VERSION ""

NS_ :

BS_:

BU_:

BO_ 2566739710 DM50: 78 Vector__XXX
 SG_ FlashRedStopLamp : 12|2@1+ (1,0) [0|3] "" Vector__XXX
 SG_ FlashProtectLamp : 8|2@1+ (1,0) [0|3] "" Vector__XXX
 SG_ FlashMalfuncIndicatorLamp : 14|2@1+ (1,0) [0|3] "" Vector__XXX
 SG_ FlashAmberWarningLamp : 10|2@1+ (1,0) [0|3] "" Vector__XXX
 SG_ MalfunctionIndicatorLampStatus : 6|2@1+ (1,0) [0|3] "" Vector__XXX
 SG_ AmberWarningLampStatus : 2|2@1+ (1,0) [0|3] "" Vector__XXX
 SG_ RedStopLampStatus : 4|2@1+ (1,0) [0|3] "" Vector__XXX
 SG_ ProtectLampStatus : 0|2@1+ (1,0) [0|3] "" Vector__XXX
 SG_ DM50_01OC : 40|7@1+ (1,0) [0|0] "" Vector__XXX
 SG_ DM50_01FMI : 32|5@1+ (1,0) [0|0] "" Vector__XXX
 SG_ DM50_01SPN : 16|16@1+ (1,0) [0|0] "" Vector__XXX
 SG_ DM50_02OC : 72|7@1+ (1,0) [0|0] "" Vector__XXX
 SG_ DM50_02FMI : 64|5@1+ (1,0) [0|0] "" Vector__XXX
 SG_ DM50_02SPN : 48|16@1+ (1,0) [0|0] "" Vector__XXX
 SG_ DM50_03OC : 104|7@1+ (1,0) [0|0] "" Vector__XXX
 SG_ DM50_03FMI : 96|5@1+ (1,0) [0|0] "" Vector__XXX
 SG_ DM50_03SPN : 80|16@1+ (1,0) [0|0] "" Vector__XXX
 SG_ DM50_04OC : 136|7@1+ (1,0) [0|0] "" Vector__XXX
 SG_ DM50_04FMI : 128|5@1+ (1,0) [0|0] "" Vector__XXX
 SG_ DM50_04SPN : 112|16@1+ (1,0) [0|0] "" Vector__XXX
 SG_ DM50_05OC : 168|7@1+ (1,0) [0|0] "" Vector__XXX
 SG_ DM50_05FMI : 160|5@1+ (1,0) [0|0] "" Vector__XXX
 SG_ DM50_05SPN : 144|16@1+ (1,0) [0|0] "" Vector__XXX
 SG_ DM50_06OC : 200|7@1+ (1,0) [0|0] "" Vector__XXX
 SG_ DM50_06FMI : 192|5@1+ (1,0) [0|0] "" Vector__XXX
 SG_ DM50_06SPN : 176|16@1+ (1,0) [0|0] "" Vector__XXX
 SG_ DM50_07OC : 232|7@1+ (1,0) [0|0] "" Vector__XXX
 SG_ DM50_07FMI : 224|5@1+ (1,0) [0|0] "" Vector__XXX
 SG_ DM50_07SPN : 208|16@1+ (1,0) [0|0] "" Vector__XXX
 SG_ DM50_08OC : 264|7@1+ (1,0) [0|0] "" Vector__XXX
 SG_ DM50_08FMI : 256|5@1+ (1,0) [0|0] "" Vector__XXX
 SG_ DM50_08SPN : 240|16@1+ (1,0) [0|0] "" Vector__XXX
 SG_ DM50_09OC : 296|7@1+ (1,0) [0|0] "" Vector__XXX
 SG_ DM50_09FMI : 288|5@1+ (1,0) [0|0] "" Vector__XXX
 SG_ DM50_09SPN : 272|16@1+ (1,0) [0|0] "" Vector__XXX
 SG_ DM50_10OC : 328|7@1+ (1,0) [0|0] "" Vector__XXX
 SG_ DM50_10FMI : 320|5@1+ (1,0) [0|0] "" Vector__XXX
 SG_ DM50_10SPN : 304|16@1+ (1,0) [0|0] "" Vector__XXX
 SG_ DM50_11OC : 360|7@1+ (1,0) [0|0] "" Vector__XXX
 SG_ DM50_11FMI : 352|5@1+ (1,0) [0|0] "" Vector__XXX
 SG_ DM50_11SPN : 336|16@1+ (1,0) [0|0] "" Vector__XXX
 SG_ DM50_12OC : 392|7@1+ (1,0) [0|0] "" Vector__XXX
 SG_ DM50_12FMI : 384|5@1+ (1,0) [0|0] "" Vector__XXX
 SG_ DM50_12SPN : 368|16@1+ (1,0) [0|0] "" Vector__XXX
 SG_ DM50_13OC : 424|7@1+ (1,0) [0|0] "" Vector__XXX
 SG_ DM50_13FMI : 416|5@1+ (1,0) [0|0] "" Vector__XXX
 SG_ DM50_13SPN : 400|16@1+ (1,0) [0|0] "" Vector__XXX
 SG_ DM50_14OC : 456|7@1+ (1,0) [0|0] "" Vector__XXX
 SG_ DM50_14FMI : 448|5@1+ (1,0) [0|0] "" Vector__XXX
 SG_ DM50_14SPN : 432|16@1+ (1,0) [0|0] "" Vector__XXX
 SG_ DM50_15OC : 488|7@1+ (1,0) [0|0] "" Vector__XXX
 SG_ DM50_15FMI : 480|5@1+ (1,0) [0|0] "" Vector__XXX
 SG_ DM50_15SPN : 464|16@1+ (1,0) [0|0] "" Vector__XXX
 SG_ DM50_16OC : 520|7@1+ (1,0) [0|0] "" Vector__XXX
 SG_ DM50_16FMI : 512|5@1+ (1,0) [0|0] "" Vector__XXX
 SG_ DM50_16SPN : 496|16@1+ (1,0) [0|0] "" Vector__XXX
 SG_ DM50_17OC : 552|7@1+ (1,0) [0|0] "" Vector__XXX
 SG_ DM50_17FMI : 544|5@1+ (1,0) [0|0] "" Vector__XXX
 SG_ DM50_17SPN : 528|16@1+ (1,0) [0|0] "" Vector__XXX
 SG_ DM50_18OC : 584|7@1+ (1,0) [0|0] "" Vector__XXX
 SG_ DM50_18FMI : 576|5@1+ (1,0) [0|0] "" Vector__XXX
 SG_ DM50_18SPN : 560|16@1+ (1,0) [0|0] "" Vector__XXX
 SG_ DM50_19OC : 616|7@1+ (1,0) [0|0] "" Vector__XXX
 SG_ DM50_19FMI : 608|5@1+ (1,0) [0|0] "" Vector__XXX
 SG_ DM50_19SPN : 592|16@1+ (1,0) [0|0] "" Vector__XXX
 SG_ DM50_19SPN_High : 613|3@1+ (65536,0) [0|0] "" Vector__XXX
 SG_ DM50_18SPN_High : 581|3@1+ (65536,0) [0|0] "" Vector__XXX
 SG_ DM50_17SPN_High : 549|3@1+ (65536,0) [0|0] "" Vector__XXX
 SG_ DM50_16SPN_High : 517|3@1+ (65536,0) [0|0] "" Vector__XXX
 SG_ DM50_15SPN_High : 485|3@1+ (65536,0) [0|0] "" Vector__XXX
 SG_ DM50_14SPN_High : 453|3@1+ (65536,0) [0|0] "" Vector__XXX
 SG_ DM50_13SPN_High : 421|3@1+ (65536,0) [0|0] "" Vector__XXX
 SG_ DM50_12SPN_High : 389|3@1+ (65536,0) [0|0] "" Vector__XXX
 SG_ DM50_11SPN_High : 357|3@1+ (65536,0) [0|0] "" Vector__XXX
 SG_ DM50_10SPN_High : 325|3@1+ (65536,0) [0|0] "" Vector__XXX
 SG_ DM50_09SPN_High : 293|3@1+ (65536,0) [0|0] "" Vector__XXX
 SG_ DM50_08SPN_High : 261|3@1+ (65536,0) [0|0] "" Vector__XXX
 SG_ DM50_07SPN_High : 229|3@1+ (65536,0) [0|0] "" Vector__XXX
 SG_ DM50_06SPN_High : 197|3@1+ (65536,0) [0|0] "" Vector__XXX
 SG_ DM50_05SPN_High : 165|3@1+ (65536,0) [0|0] "" Vector__XXX
 SG_ DM50_04SPN_High : 133|3@1+ (65536,0) [0|0] "" Vector__XXX
 SG_ DM50_03SPN_High : 101|3@1+ (65536,0) [0|0] "" Vector__XXX
 SG_ DM50_02SPN_High : 69|3@1+ (65536,0) [0|0] "" Vector__XXX
 SG_ DM50_01SPN_High : 37|3@1+ (65536,0) [0|0] "" Vector__XXX
 SG_ DM50_01CM : 47|1@1+ (1,0) [0|0] "" Vector__XXX
 SG_ DM50_02CM : 79|1@1+ (1,0) [0|0] "" Vector__XXX
 SG_ DM50_03CM : 111|1@1+ (1,0) [0|0] "" Vector__XXX
 SG_ DM50_04CM : 143|1@1+ (1,0) [0|0] "" Vector__XXX
 SG_ DM50_05CM : 175|1@1+ (1,0) [0|0] "" Vector__XXX
 SG_ DM50_06CM : 207|1@1+ (1,0) [0|0] "" Vector__XXX
 SG_ DM50_07CM : 239|1@1+ (1,0) [0|0] "" Vector__XXX
 SG_ DM50_08CM : 271|1@1+ (1,0) [0|0] "" Vector__XXX
 SG_ DM50_09CM : 303|1@1+ (1,0) [0|0] "" Vector__XXX
 SG_ DM50_10CM : 335|1@1+ (1,0) [0|0] "" Vector__XXX
 SG_ DM50_11CM : 367|1@1+ (1,0) [0|0] "" Vector__XXX
 SG_ DM50_12CM : 399|1@1+ (1,0) [0|0] "" Vector__XXX
 SG_ DM50_13CM : 431|1@1+ (1,0) [0|0] "" Vector__XXX
 SG_ DM50_14CM : 463|1@1+ (1,0) [0|0] "" Vector__XXX
 SG_ DM50_15CM : 495|1@1+ (1,0) [0|0] "" Vector__XXX
 SG_ DM50_16CM : 527|1@1+ (1,0) [0|0] "" Vector__XXX
 SG_ DM50_17CM : 559|1@1+ (1,0) [0|0] "" Vector__XXX
 SG_ DM50_18CM : 591|1@1+ (1,0) [0|0] "" Vector__XXX
 SG_ DM50_19CM : 623|1@1+ (1,0) [0|0] "" Vector__XXX

BO_ 2566739966 DM49: 78 Vector__XXX
 SG_ FlashRedStopLamp : 12|2@1+ (1,0) [0|3] "" Vector__XXX
 SG_ FlashProtectLamp : 8|2@1+ (1,0) [0|3] "" Vector__XXX
 SG_ FlashMalfuncIndicatorLamp : 14|2@1+ (1,0) [0|3] "" Vector__XXX
 SG_ FlashAmberWarningLamp : 10|2@1+ (1,0) [0|3] "" Vector__XXX
 SG_ MalfunctionIndicatorLampStatus : 6|2@1+ (1,0) [0|3] "" Vector__XXX
 SG_ AmberWarningLampStatus : 2|2@1+ (1,0) [0|3] "" Vector__XXX
 SG_ RedStopLampStatus : 4|2@1+ (1,0) [0|3] "" Vector__XXX
 SG_ ProtectLampStatus : 0|2@1+ (1,0) [0|3] "" Vector__XXX
 SG_ DM49_01OC : 40|7@1+ (1,0) [0|0] "" Vector__XXX
 SG_ DM49_01FMI : 32|5@1+ (1,0) [0|0] "" Vector__XXX
 SG_ DM49_01SPN : 16|16@1+ (1,0) [0|0] "" Vector__XXX
 SG_ DM49_02OC : 72|7@1+ (1,0) [0|0] "" Vector__XXX
 SG_ DM49_02FMI : 64|5@1+ (1,0) [0|0] "" Vector__XXX
 SG_ DM49_02SPN : 48|16@1+ (1,0) [0|0] "" Vector__XXX
 SG_ DM49_03OC : 104|7@1+ (1,0) [0|0] "" Vector__XXX
 SG_ DM49_03FMI : 96|5@1+ (1,0) [0|0] "" Vector__XXX
 SG_ DM49_03SPN : 80|16@1+ (1,0) [0|0] "" Vector__XXX
 SG_ DM49_04OC : 136|7@1+ (1,0) [0|0] "" Vector__XXX
 SG_ DM49_04FMI : 128|5@1+ (1,0) [0|0] "" Vector__XXX
 SG_ DM49_04SPN : 112|16@1+ (1,0) [0|0] "" Vector__XXX
 SG_ DM49_05OC : 168|7@1+ (1,0) [0|0] "" Vector__XXX
 SG_ DM49_05FMI : 160|5@1+ (1,0) [0|0] "" Vector__XXX
 SG_ DM49_05SPN : 144|16@1+ (1,0) [0|0] "" Vector__XXX
 SG_ DM49_06OC : 200|7@1+ (1,0) [0|0] "" Vector__XXX
 SG_ DM49_06FMI : 192|5@1+ (1,0) [0|0] "" Vector__XXX
 SG_ DM49_06SPN : 176|16@1+ (1,0) [0|0] "" Vector__XXX
 SG_ DM49_07OC : 232|7@1+ (1,0) [0|0] "" Vector__XXX
 SG_ DM49_07FMI : 224|5@1+ (1,0) [0|0] "" Vector__XXX
 SG_ DM49_07SPN : 208|16@1+ (1,0) [0|0] "" Vector__XXX
 SG_ DM49_08OC : 264|7@1+ (1,0) [0|0] "" Vector__XXX
 SG_ DM49_08FMI : 256|5@1+ (1,0) [0|0] "" Vector__XXX
 SG_ DM49_08SPN : 240|16@1+ (1,0) [0|0] "" Vector__XXX
 SG_ DM49_09OC : 296|7@1+ (1,0) [0|0] "" Vector__XXX
 SG_ DM49_09FMI : 288|5@1+ (1,0) [0|0] "" Vector__XXX
 SG_ DM49_09SPN : 272|16@1+ (1,0) [0|0] "" Vector__XXX
 SG_ DM49_10OC : 328|7@1+ (1,0) [0|0] "" Vector__XXX
 SG_ DM49_10FMI : 320|5@1+ (1,0) [0|0] "" Vector__XXX
 SG_ DM49_10SPN : 304|16@1+ (1,0) [0|0] "" Vector__XXX
 SG_ DM49_11OC : 360|7@1+ (1,0) [0|0] "" Vector__XXX
 SG_ DM49_11FMI : 352|5@1+ (1,0) [0|0] "" Vector__XXX
 SG_ DM49_11SPN : 336|16@1+ (1,0) [0|0] "" Vector__XXX
 SG_ DM49_12OC : 392|7@1+ (1,0) [0|0] "" Vector__XXX
 SG_ DM49_12FMI : 384|5@1+ (1,0) [0|0] "" Vector__XXX
 SG_ DM49_12SPN : 368|16@1+ (1,0) [0|0] "" Vector__XXX
 SG_ DM49_13OC : 424|7@1+ (1,0) [0|0] "" Vector__XXX
 SG_ DM49_13FMI : 416|5@1+ (1,0) [0|0] "" Vector__XXX
 SG_ DM49_13SPN : 400|16@1+ (1,0) [0|0] "" Vector__XXX
 SG_ DM49_14OC : 456|7@1+ (1,0) [0|0] "" Vector__XXX
 SG_ DM49_14FMI : 448|5@1+ (1,0) [0|0] "" Vector__XXX
 SG_ DM49_14SPN : 432|16@1+ (1,0) [0|0] "" Vector__XXX
 SG_ DM49_15OC : 488|7@1+ (1,0) [0|0] "" Vector__XXX
 SG_ DM49_15FMI : 480|5@1+ (1,0) [0|0] "" Vector__XXX
 SG_ DM49_15SPN : 464|16@1+ (1,0) [0|0] "" Vector__XXX
 SG_ DM49_16OC : 520|7@1+ (1,0) [0|0] "" Vector__XXX
 SG_ DM49_16FMI : 512|5@1+ (1,0) [0|0] "" Vector__XXX
 SG_ DM49_16SPN : 496|16@1+ (1,0) [0|0] "" Vector__XXX
 SG_ DM49_17OC : 552|7@1+ (1,0) [0|0] "" Vector__XXX
 SG_ DM49_17FMI : 544|5@1+ (1,0) [0|0] "" Vector__XXX
 SG_ DM49_17SPN : 528|16@1+ (1,0) [0|0] "" Vector__XXX
 SG_ DM49_18OC : 584|7@1+ (1,0) [0|0] "" Vector__XXX
 SG_ DM49_18FMI : 576|5@1+ (1,0) [0|0] "" Vector__XXX
 SG_ DM49_18SPN : 560|16@1+ (1,0) [0|0] "" Vector__XXX
 SG_ DM49_19OC : 616|7@1+ (1,0) [0|0] "" Vector__XXX
 SG_ DM49_19FMI : 608|5@1+ (1,0) [0|0] "" Vector__XXX
 SG_ DM49_19SPN : 592|16@1+ (1,0) [0|0] "" Vector__XXX
 SG_ DM49_19SPN_High : 613|3@1+ (65536,0) [0|0] "" Vector__XXX
 SG_ DM49_18SPN_High : 581|3@1+ (65536,0) [0|0] "" Vector__XXX
 SG_ DM49_17SPN_High : 549|3@1+ (65536,0) [0|0] "" Vector__XXX
 SG_ DM49_16SPN_High : 517|3@1+ (65536,0) [0|0] "" Vector__XXX
 SG_ DM49_15SPN_High : 485|3@1+ (65536,0) [0|0] "" Vector__XXX
 SG_ DM49_14SPN_High : 453|3@1+ (65536,0) [0|0] "" Vector__XXX
 SG_ DM49_13SPN_High : 421|3@1+ (65536,0) [0|0] "" Vector__XXX
 SG_ DM49_12SPN_High : 389|3@1+ (65536,0) [0|0] "" Vector__XXX
 SG_ DM49_11SPN_High : 357|3@1+ (65536,0) [0|0] "" Vector__XXX
 SG_ DM49_10SPN_High : 325|3@1+ (65536,0) [0|0] "" Vector__XXX
 SG_ DM49_09SPN_High : 293|3@1+ (65536,0) [0|0] "" Vector__XXX
 SG_ DM49_08SPN_High : 261|3@1+ (65536,0) [0|0] "" Vector__XXX
 SG_ DM49_07SPN_High : 229|3@1+ (65536,0) [0|0] "" Vector__XXX
 SG_ DM49_06SPN_High : 197|3@1+ (65536,0) [0|0] "" Vector__XXX
 SG_ DM49_05SPN_High : 165|3@1+ (65536,0) [0|0] "" Vector__XXX
 SG_ DM49_04SPN_High : 133|3@1+ (65536,0) [0|0] "" Vector__XXX
 SG_ DM49_03SPN_High : 101|3@1+ (65536,0) [0|0] "" Vector__XXX
 SG_ DM49_02SPN_High : 69|3@1+ (65536,0) [0|0] "" Vector__XXX
 SG_ DM49_01SPN_High : 37|3@1+ (65536,0) [0|0] "" Vector__XXX
 SG_ DM49_01CM : 47|1@1+ (1,0) [0|0] "" Vector__XXX
 SG_ DM49_02CM : 79|1@1+ (1,0) [0|0] "" Vector__XXX
 SG_ DM49_03CM : 111|1@1+ (1,0) [0|0] "" Vector__XXX
 SG_ DM49_04CM : 143|1@1+ (1,0) [0|0] "" Vector__XXX
 SG_ DM49_05CM : 175|1@1+ (1,0) [0|0] "" Vector__XXX
 SG_ DM49_06CM : 207|1@1+ (1,0) [0|0] "" Vector__XXX
 SG_ DM49_07CM : 239|1@1+ (1,0) [0|0] "" Vector__XXX
 SG_ DM49_08CM : 271|1@1+ (1,0) [0|0] "" Vector__XXX
 SG_ DM49_09CM : 303|1@1+ (1,0) [0|0] "" Vector__XXX
 SG_ DM49_10CM : 335|1@1+ (1,0) [0|0] "" Vector__XXX
 SG_ DM49_11CM : 367|1@1+ (1,0) [0|0] "" Vector__XXX
 SG_ DM49_12CM : 399|1@1+ (1,0) [0|0] "" Vector__XXX
 SG_ DM49_13CM : 431|1@1+ (1,0) [0|0] "" Vector__XXX
 SG_ DM49_14CM : 463|1@1+ (1,0) [0|0] "" Vector__XXX
 SG_ DM49_15CM : 495|1@1+ (1,0) [0|0] "" Vector__XXX
 SG_ DM49_16CM : 527|1@1+ (1,0) [0|0] "" Vector__XXX
 SG_ DM49_17CM : 559|1@1+ (1,0) [0|0] "" Vector__XXX
 SG_ DM49_18CM : 591|1@1+ (1,0) [0|0] "" Vector__XXX
 SG_ DM49_19CM : 623|1@1+ (1,0) [0|0] "" Vector__XXX

BO_ 2566740222 DM48: 78 Vector__XXX
 SG_ FlashRedStopLamp : 12|2@1+ (1,0) [0|3] "" Vector__XXX
 SG_ FlashProtectLamp : 8|2@1+ (1,0) [0|3] "" Vector__XXX
 SG_ FlashMalfuncIndicatorLamp : 14|2@1+ (1,0) [0|3] "" Vector__XXX
 SG_ FlashAmberWarningLamp : 10|2@1+ (1,0) [0|3] "" Vector__XXX
 SG_ MalfunctionIndicatorLampStatus : 6|2@1+ (1,0) [0|3] "" Vector__XXX
 SG_ AmberWarningLampStatus : 2|2@1+ (1,0) [0|3] "" Vector__XXX
 SG_ RedStopLampStatus : 4|2@1+ (1,0) [0|3] "" Vector__XXX
 SG_ ProtectLampStatus : 0|2@1+ (1,0) [0|3] "" Vector__XXX
 SG_ DM48_01OC : 40|7@1+ (1,0) [0|0] "" Vector__XXX
 SG_ DM48_01FMI : 32|5@1+ (1,0) [0|0] "" Vector__XXX
 SG_ DM48_01SPN : 16|16@1+ (1,0) [0|0] "" Vector__XXX
 SG_ DM48_02OC : 72|7@1+ (1,0) [0|0] "" Vector__XXX
 SG_ DM48_02FMI : 64|5@1+ (1,0) [0|0] "" Vector__XXX
 SG_ DM48_02SPN : 48|16@1+ (1,0) [0|0] "" Vector__XXX
 SG_ DM48_03OC : 104|7@1+ (1,0) [0|0] "" Vector__XXX
 SG_ DM48_03FMI : 96|5@1+ (1,0) [0|0] "" Vector__XXX
 SG_ DM48_03SPN : 80|16@1+ (1,0) [0|0] "" Vector__XXX
 SG_ DM48_04OC : 136|7@1+ (1,0) [0|0] "" Vector__XXX
 SG_ DM48_04FMI : 128|5@1+ (1,0) [0|0] "" Vector__XXX
 SG_ DM48_04SPN : 112|16@1+ (1,0) [0|0] "" Vector__XXX
 SG_ DM48_05OC : 168|7@1+ (1,0) [0|0] "" Vector__XXX
 SG_ DM48_05FMI : 160|5@1+ (1,0) [0|0] "" Vector__XXX
 SG_ DM48_05SPN : 144|16@1+ (1,0) [0|0] "" Vector__XXX
 SG_ DM48_06OC : 200|7@1+ (1,0) [0|0] "" Vector__XXX
 SG_ DM48_06FMI : 192|5@1+ (1,0) [0|0] "" Vector__XXX
 SG_ DM48_06SPN : 176|16@1+ (1,0) [0|0] "" Vector__XXX
 SG_ DM48_07OC : 232|7@1+ (1,0) [0|0] "" Vector__XXX
 SG_ DM48_07FMI : 224|5@1+ (1,0) [0|0] "" Vector__XXX
 SG_ DM48_07SPN : 208|16@1+ (1,0) [0|0] "" Vector__XXX
 SG_ DM48_08OC : 264|7@1+ (1,0) [0|0] "" Vector__XXX
 SG_ DM48_08FMI : 256|5@1+ (1,0) [0|0] "" Vector__XXX
 SG_ DM48_08SPN : 240|16@1+ (1,0) [0|0] "" Vector__XXX
 SG_ DM48_09OC : 296|7@1+ (1,0) [0|0] "" Vector__XXX
 SG_ DM48_09FMI : 288|5@1+ (1,0) [0|0] "" Vector__XXX
 SG_ DM48_09SPN : 272|16@1+ (1,0) [0|0] "" Vector__XXX
 SG_ DM48_10OC : 328|7@1+ (1,0) [0|0] "" Vector__XXX
 SG_ DM48_10FMI : 320|5@1+ (1,0) [0|0] "" Vector__XXX
 SG_ DM48_10SPN : 304|16@1+ (1,0) [0|0] "" Vector__XXX
 SG_ DM48_11OC : 360|7@1+ (1,0) [0|0] "" Vector__XXX
 SG_ DM48_11FMI : 352|5@1+ (1,0) [0|0] "" Vector__XXX
 SG_ DM48_11SPN : 336|16@1+ (1,0) [0|0] "" Vector__XXX
 SG_ DM48_12OC : 392|7@1+ (1,0) [0|0] "" Vector__XXX
 SG_ DM48_12FMI : 384|5@1+ (1,0) [0|0] "" Vector__XXX
 SG_ DM48_12SPN : 368|16@1+ (1,0) [0|0] "" Vector__XXX
 SG_ DM48_13OC : 424|7@1+ (1,0) [0|0] "" Vector__XXX
 SG_ DM48_13FMI : 416|5@1+ (1,0) [0|0] "" Vector__XXX
 SG_ DM48_13SPN : 400|16@1+ (1,0) [0|0] "" Vector__XXX
 SG_ DM48_14OC : 456|7@1+ (1,0) [0|0] "" Vector__XXX
 SG_ DM48_14FMI : 448|5@1+ (1,0) [0|0] "" Vector__XXX
 SG_ DM48_14SPN : 432|16@1+ (1,0) [0|0] "" Vector__XXX
 SG_ DM48_15OC : 488|7@1+ (1,0) [0|0] "" Vector__XXX
 SG_ DM48_15FMI : 480|5@1+ (1,0) [0|0] "" Vector__XXX
 SG_ DM48_15SPN : 464|16@1+ (1,0) [0|0] "" Vector__XXX
 SG_ DM48_16OC : 520|7@1+ (1,0) [0|0] "" Vector__XXX
 SG_ DM48_16FMI : 512|5@1+ (1,0) [0|0] "" Vector__XXX
 SG_ DM48_16SPN : 496|16@1+ (1,0) [0|0] "" Vector__XXX
 SG_ DM48_17OC : 552|7@1+ (1,0) [0|0] "" Vector__XXX
 SG_ DM48_17FMI : 544|5@1+ (1,0) [0|0] "" Vector__XXX
 SG_ DM48_17SPN : 528|16@1+ (1,0) [0|0] "" Vector__XXX
 SG_ DM48_18OC : 584|7@1+ (1,0) [0|0] "" Vector__XXX
 SG_ DM48_18FMI : 576|5@1+ (1,0) [0|0] "" Vector__XXX
 SG_ DM48_18SPN : 560|16@1+ (1,0) [0|0] "" Vector__XXX
 SG_ DM48_19OC : 616|7@1+ (1,0) [0|0] "" Vector__XXX
 SG_ DM48_19FMI : 608|5@1+ (1,0) [0|0] "" Vector__XXX
 SG_ DM48_19SPN : 592|16@1+ (1,0) [0|0] "" Vector__XXX
 SG_ DM48_19SPN_High : 613|3@1+ (65536,0) [0|0] "" Vector__XXX
 SG_ DM48_18SPN_High : 581|3@1+ (65536,0) [0|0] "" Vector__XXX
 SG_ DM48_17SPN_High : 549|3@1+ (65536,0) [0|0] "" Vector__XXX
 SG_ DM48_16SPN_High : 517|3@1+ (65536,0) [0|0] "" Vector__XXX
 SG_ DM48_15SPN_High : 485|3@1+ (65536,0) [0|0] "" Vector__XXX
 SG_ DM48_14SPN_High : 453|3@1+ (65536,0) [0|0] "" Vector__XXX
 SG_ DM48_13SPN_High : 421|3@1+ (65536,0) [0|0] "" Vector__XXX
 SG_ DM48_12SPN_High : 389|3@1+ (65536,0) [0|0] "" Vector__XXX
 SG_ DM48_11SPN_High : 357|3@1+ (65536,0) [0|0] "" Vector__XXX
 SG_ DM48_10SPN_High : 325|3@1+ (65536,0) [0|0] "" Vector__XXX
 SG_ DM48_09SPN_High : 293|3@1+ (65536,0) [0|0] "" Vector__XXX
 SG_ DM48_08SPN_High : 261|3@1+ (65536,0) [0|0] "" Vector__XXX
 SG_ DM48_07SPN_High : 229|3@1+ (65536,0) [0|0] "" Vector__XXX
 SG_ DM48_06SPN_High : 197|3@1+ (65536,0) [0|0] "" Vector__XXX
 SG_ DM48_05SPN_High : 165|3@1+ (65536,0) [0|0] "" Vector__XXX
 SG_ DM48_04SPN_High : 133|3@1+ (65536,0) [0|0] "" Vector__XXX
 SG_ DM48_03SPN_High : 101|3@1+ (65536,0) [0|0] "" Vector__XXX
 SG_ DM48_02SPN_High : 69|3@1+ (65536,0) [0|0] "" Vector__XXX
 SG_ DM48_01SPN_High : 37|3@1+ (65536,0) [0|0] "" Vector__XXX
 SG_ DM48_01CM : 47|1@1+ (1,0) [0|0] "" Vector__XXX
 SG_ DM48_02CM : 79|1@1+ (1,0) [0|0] "" Vector__XXX
 SG_ DM48_03CM : 111|1@1+ (1,0) [0|0] "" Vector__XXX
 SG_ DM48_04CM : 143|1@1+ (1,0) [0|0] "" Vector__XXX
 SG_ DM48_05CM : 175|1@1+ (1,0) [0|0] "" Vector__XXX
 SG_ DM48_06CM : 207|1@1+ (1,0) [0|0] "" Vector__XXX
 SG_ DM48_07CM : 239|1@1+ (1,0) [0|0] "" Vector__XXX
 SG_ DM48_08CM : 271|1@1+ (1,0) [0|0] "" Vector__XXX
 SG_ DM48_09CM : 303|1@1+ (1,0) [0|0] "" Vector__XXX
 SG_ DM48_10CM : 335|1@1+ (1,0) [0|0] "" Vector__XXX
 SG_ DM48_11CM : 367|1@1+ (1,0) [0|0] "" Vector__XXX
 SG_ DM48_12CM : 399|1@1+ (1,0) [0|0] "" Vector__XXX
 SG_ DM48_13CM : 431|1@1+ (1,0) [0|0] "" Vector__XXX
 SG_ DM48_14CM : 463|1@1+ (1,0) [0|0] "" Vector__XXX
 SG_ DM48_15CM : 495|1@1+ (1,0) [0|0] "" Vector__XXX
 SG_ DM48_16CM : 527|1@1+ (1,0) [0|0] "" Vector__XXX
 SG_ DM48_17CM : 559|1@1+ (1,0) [0|0] "" Vector__XXX
 SG_ DM48_18CM : 591|1@1+ (1,0) [0|0] "" Vector__XXX
 SG_ DM48_19CM : 623|1@1+ (1,0) [0|0] "" Vector__XXX

BO_ 2566740478 DM47: 78 Vector__XXX
 SG_ FlashRedStopLamp : 12|2@1+ (1,0) [0|3] "" Vector__XXX
 SG_ FlashProtectLamp : 8|2@1+ (1,0) [0|3] "" Vector__XXX
 SG_ FlashMalfuncIndicatorLamp : 14|2@1+ (1,0) [0|3] "" Vector__XXX
 SG_ FlashAmberWarningLamp : 10|2@1+ (1,0) [0|3] "" Vector__XXX
 SG_ MalfunctionIndicatorLampStatus : 6|2@1+ (1,0) [0|3] "" Vector__XXX
 SG_ AmberWarningLampStatus : 2|2@1+ (1,0) [0|3] "" Vector__XXX
 SG_ RedStopLampStatus : 4|2@1+ (1,0) [0|3] "" Vector__XXX
 SG_ ProtectLampStatus : 0|2@1+ (1,0) [0|3] "" Vector__XXX
 SG_ DM47_01OC : 40|7@1+ (1,0) [0|0] "" Vector__XXX
 SG_ DM47_01FMI : 32|5@1+ (1,0) [0|0] "" Vector__XXX
 SG_ DM47_01SPN : 16|16@1+ (1,0) [0|0] "" Vector__XXX
 SG_ DM47_02OC : 72|7@1+ (1,0) [0|0] "" Vector__XXX
 SG_ DM47_02FMI : 64|5@1+ (1,0) [0|0] "" Vector__XXX
 SG_ DM47_02SPN : 48|16@1+ (1,0) [0|0] "" Vector__XXX
 SG_ DM47_03OC : 104|7@1+ (1,0) [0|0] "" Vector__XXX
 SG_ DM47_03FMI : 96|5@1+ (1,0) [0|0] "" Vector__XXX
 SG_ DM47_03SPN : 80|16@1+ (1,0) [0|0] "" Vector__XXX
 SG_ DM47_04OC : 136|7@1+ (1,0) [0|0] "" Vector__XXX
 SG_ DM47_04FMI : 128|5@1+ (1,0) [0|0] "" Vector__XXX
 SG_ DM47_04SPN : 112|16@1+ (1,0) [0|0] "" Vector__XXX
 SG_ DM47_05OC : 168|7@1+ (1,0) [0|0] "" Vector__XXX
 SG_ DM47_05FMI : 160|5@1+ (1,0) [0|0] "" Vector__XXX
 SG_ DM47_05SPN : 144|16@1+ (1,0) [0|0] "" Vector__XXX
 SG_ DM47_06OC : 200|7@1+ (1,0) [0|0] "" Vector__XXX
 SG_ DM47_06FMI : 192|5@1+ (1,0) [0|0] "" Vector__XXX
 SG_ DM47_06SPN : 176|16@1+ (1,0) [0|0] "" Vector__XXX
 SG_ DM47_07OC : 232|7@1+ (1,0) [0|0] "" Vector__XXX
 SG_ DM47_07FMI : 224|5@1+ (1,0) [0|0] "" Vector__XXX
 SG_ DM47_07SPN : 208|16@1+ (1,0) [0|0] "" Vector__XXX
 SG_ DM47_08OC : 264|7@1+ (1,0) [0|0] "" Vector__XXX
 SG_ DM47_08FMI : 256|5@1+ (1,0) [0|0] "" Vector__XXX
 SG_ DM47_08SPN : 240|16@1+ (1,0) [0|0] "" Vector__XXX
 SG_ DM47_09OC : 296|7@1+ (1,0) [0|0] "" Vector__XXX
 SG_ DM47_09FMI : 288|5@1+ (1,0) [0|0] "" Vector__XXX
 SG_ DM47_09SPN : 272|16@1+ (1,0) [0|0] "" Vector__XXX
 SG_ DM47_10OC : 328|7@1+ (1,0) [0|0] "" Vector__XXX
 SG_ DM47_10FMI : 320|5@1+ (1,0) [0|0] "" Vector__XXX
 SG_ DM47_10SPN : 304|16@1+ (1,0) [0|0] "" Vector__XXX
 SG_ DM47_11OC : 360|7@1+ (1,0) [0|0] "" Vector__XXX
 SG_ DM47_11FMI : 352|5@1+ (1,0) [0|0] "" Vector__XXX
 SG_ DM47_11SPN : 336|16@1+ (1,0) [0|0] "" Vector__XXX
 SG_ DM47_12OC : 392|7@1+ (1,0) [0|0] "" Vector__XXX
 SG_ DM47_12FMI : 384|5@1+ (1,0) [0|0] "" Vector__XXX
 SG_ DM47_12SPN : 368|16@1+ (1,0) [0|0] "" Vector__XXX
 SG_ DM47_13OC : 424|7@1+ (1,0) [0|0] "" Vector__XXX
 SG_ DM47_13FMI : 416|5@1+ (1,0) [0|0] "" Vector__XXX
 SG_ DM47_13SPN : 400|16@1+ (1,0) [0|0] "" Vector__XXX
 SG_ DM47_14OC : 456|7@1+ (1,0) [0|0] "" Vector__XXX
 SG_ DM47_14FMI : 448|5@1+ (1,0) [0|0] "" Vector__XXX
 SG_ DM47_14SPN : 432|16@1+ (1,0) [0|0] "" Vector__XXX
 SG_ DM47_15OC : 488|7@1+ (1,0) [0|0] "" Vector__XXX
 SG_ DM47_15FMI : 480|5@1+ (1,0) [0|0] "" Vector__XXX
 SG_ DM47_15SPN : 464|16@1+ (1,0) [0|0] "" Vector__XXX
 SG_ DM47_16OC : 520|7@1+ (1,0) [0|0] "" Vector__XXX
 SG_ DM47_16FMI : 512|5@1+ (1,0) [0|0] "" Vector__XXX
 SG_ DM47_16SPN : 496|16@1+ (1,0) [0|0] "" Vector__XXX
 SG_ DM47_17OC : 552|7@1+ (1,0) [0|0] "" Vector__XXX
 SG_ DM47_17FMI : 544|5@1+ (1,0) [0|0] "" Vector__XXX
 SG_ DM47_17SPN : 528|16@1+ (1,0) [0|0] "" Vector__XXX
 SG_ DM47_18OC : 584|7@1+ (1,0) [0|0] "" Vector__XXX
 SG_ DM47_18FMI : 576|5@1+ (1,0) [0|0] "" Vector__XXX
 SG_ DM47_18SPN : 560|16@1+ (1,0) [0|0] "" Vector__XXX
 SG_ DM47_19OC : 616|7@1+ (1,0) [0|0] "" Vector__XXX
 SG_ DM47_19FMI : 608|5@1+ (1,0) [0|0] "" Vector__XXX
 SG_ DM47_19SPN : 592|16@1+ (1,0) [0|0] "" Vector__XXX
 SG_ DM47_19SPN_High : 613|3@1+ (65536,0) [0|0] "" Vector__XXX
 SG_ DM47_18SPN_High : 581|3@1+ (65536,0) [0|0] "" Vector__XXX
 SG_ DM47_17SPN_High : 549|3@1+ (65536,0) [0|0] "" Vector__XXX
 SG_ DM47_16SPN_High : 517|3@1+ (65536,0) [0|0] "" Vector__XXX
 SG_ DM47_15SPN_High : 485|3@1+ (65536,0) [0|0] "" Vector__XXX
 SG_ DM47_14SPN_High : 453|3@1+ (65536,0) [0|0] "" Vector__XXX
 SG_ DM47_13SPN_High : 421|3@1+ (65536,0) [0|0] "" Vector__XXX
 SG_ DM47_12SPN_High : 389|3@1+ (65536,0) [0|0] "" Vector__XXX
 SG_ DM47_11SPN_High : 357|3@1+ (65536,0) [0|0] "" Vector__XXX
 SG_ DM47_10SPN_High : 325|3@1+ (65536,0) [0|0] "" Vector__XXX
 SG_ DM47_09SPN_High : 293|3@1+ (65536,0) [0|0] "" Vector__XXX
 SG_ DM47_08SPN_High : 261|3@1+ (65536,0) [0|0] "" Vector__XXX
 SG_ DM47_07SPN_High : 229|3@1+ (65536,0) [0|0] "" Vector__XXX
 SG_ DM47_06SPN_High : 197|3@1+ (65536,0) [0|0] "" Vector__XXX
 SG_ DM47_05SPN_High : 165|3@1+ (65536,0) [0|0] "" Vector__XXX
 SG_ DM47_04SPN_High : 133|3@1+ (65536,0) [0|0] "" Vector__XXX
 SG_ DM47_03SPN_High : 101|3@1+ (65536,0) [0|0] "" Vector__XXX
 SG_ DM47_02SPN_High : 69|3@1+ (65536,0) [0|0] "" Vector__XXX
 SG_ DM47_01SPN_High : 37|3@1+ (65536,0) [0|0] "" Vector__XXX
 SG_ DM47_01CM : 47|1@1+ (1,0) [0|0] "" Vector__XXX
 SG_ DM47_02CM : 79|1@1+ (1,0) [0|0] "" Vector__XXX
 SG_ DM47_03CM : 111|1@1+ (1,0) [0|0] "" Vector__XXX
 SG_ DM47_04CM : 143|1@1+ (1,0) [0|0] "" Vector__XXX
 SG_ DM47_05CM : 175|1@1+ (1,0) [0|0] "" Vector__XXX
 SG_ DM47_06CM : 207|1@1+ (1,0) [0|0] "" Vector__XXX
 SG_ DM47_07CM : 239|1@1+ (1,0) [0|0] "" Vector__XXX
 SG_ DM47_08CM : 271|1@1+ (1,0) [0|0] "" Vector__XXX
 SG_ DM47_09CM : 303|1@1+ (1,0) [0|0] "" Vector__XXX
 SG_ DM47_10CM : 335|1@1+ (1,0) [0|0] "" Vector__XXX
 SG_ DM47_11CM : 367|1@1+ (1,0) [0|0] "" Vector__XXX
 SG_ DM47_12CM : 399|1@1+ (1,0) [0|0] "" Vector__XXX
 SG_ DM47_13CM : 431|1@1+ (1,0) [0|0] "" Vector__XXX
 SG_ DM47_14CM : 463|1@1+ (1,0) [0|0] "" Vector__XXX
 SG_ DM47_15CM : 495|1@1+ (1,0) [0|0] "" Vector__XXX
 SG_ DM47_16CM : 527|1@1+ (1,0) [0|0] "" Vector__XXX
 SG_ DM47_17CM : 559|1@1+ (1,0) [0|0] "" Vector__XXX
 SG_ DM47_18CM : 591|1@1+ (1,0) [0|0] "" Vector__XXX
 SG_ DM47_19CM : 623|1@1+ (1,0) [0|0] "" Vector__XXX

BO_ 2566740734 DM46: 78 Vector__XXX
 SG_ FlashRedStopLamp : 12|2@1+ (1,0) [0|3] "" Vector__XXX
 SG_ FlashProtectLamp : 8|2@1+ (1,0) [0|3] "" Vector__XXX
 SG_ FlashMalfuncIndicatorLamp : 14|2@1+ (1,0) [0|3] "" Vector__XXX
 SG_ FlashAmberWarningLamp : 10|2@1+ (1,0) [0|3] "" Vector__XXX
 SG_ MalfunctionIndicatorLampStatus : 6|2@1+ (1,0) [0|3] "" Vector__XXX
 SG_ AmberWarningLampStatus : 2|2@1+ (1,0) [0|3] "" Vector__XXX
 SG_ RedStopLampStatus : 4|2@1+ (1,0) [0|3] "" Vector__XXX
 SG_ ProtectLampStatus : 0|2@1+ (1,0) [0|3] "" Vector__XXX
 SG_ DM46_01OC : 40|7@1+ (1,0) [0|0] "" Vector__XXX
 SG_ DM46_01FMI : 32|5@1+ (1,0) [0|0] "" Vector__XXX
 SG_ DM46_01SPN : 16|16@1+ (1,0) [0|0] "" Vector__XXX
 SG_ DM46_02OC : 72|7@1+ (1,0) [0|0] "" Vector__XXX
 SG_ DM46_02FMI : 64|5@1+ (1,0) [0|0] "" Vector__XXX
 SG_ DM46_02SPN : 48|16@1+ (1,0) [0|0] "" Vector__XXX
 SG_ DM46_03OC : 104|7@1+ (1,0) [0|0] "" Vector__XXX
 SG_ DM46_03FMI : 96|5@1+ (1,0) [0|0] "" Vector__XXX
 SG_ DM46_03SPN : 80|16@1+ (1,0) [0|0] "" Vector__XXX
 SG_ DM46_04OC : 136|7@1+ (1,0) [0|0] "" Vector__XXX
 SG_ DM46_04FMI : 128|5@1+ (1,0) [0|0] "" Vector__XXX
 SG_ DM46_04SPN : 112|16@1+ (1,0) [0|0] "" Vector__XXX
 SG_ DM46_05OC : 168|7@1+ (1,0) [0|0] "" Vector__XXX
 SG_ DM46_05FMI : 160|5@1+ (1,0) [0|0] "" Vector__XXX
 SG_ DM46_05SPN : 144|16@1+ (1,0) [0|0] "" Vector__XXX
 SG_ DM46_06OC : 200|7@1+ (1,0) [0|0] "" Vector__XXX
 SG_ DM46_06FMI : 192|5@1+ (1,0) [0|0] "" Vector__XXX
 SG_ DM46_06SPN : 176|16@1+ (1,0) [0|0] "" Vector__XXX
 SG_ DM46_07OC : 232|7@1+ (1,0) [0|0] "" Vector__XXX
 SG_ DM46_07FMI : 224|5@1+ (1,0) [0|0] "" Vector__XXX
 SG_ DM46_07SPN : 208|16@1+ (1,0) [0|0] "" Vector__XXX
 SG_ DM46_08OC : 264|7@1+ (1,0) [0|0] "" Vector__XXX
 SG_ DM46_08FMI : 256|5@1+ (1,0) [0|0] "" Vector__XXX
 SG_ DM46_08SPN : 240|16@1+ (1,0) [0|0] "" Vector__XXX
 SG_ DM46_09OC : 296|7@1+ (1,0) [0|0] "" Vector__XXX
 SG_ DM46_09FMI : 288|5@1+ (1,0) [0|0] "" Vector__XXX
 SG_ DM46_09SPN : 272|16@1+ (1,0) [0|0] "" Vector__XXX
 SG_ DM46_10OC : 328|7@1+ (1,0) [0|0] "" Vector__XXX
 SG_ DM46_10FMI : 320|5@1+ (1,0) [0|0] "" Vector__XXX
 SG_ DM46_10SPN : 304|16@1+ (1,0) [0|0] "" Vector__XXX
 SG_ DM46_11OC : 360|7@1+ (1,0) [0|0] "" Vector__XXX
 SG_ DM46_11FMI : 352|5@1+ (1,0) [0|0] "" Vector__XXX
 SG_ DM46_11SPN : 336|16@1+ (1,0) [0|0] "" Vector__XXX
 SG_ DM46_12OC : 392|7@1+ (1,0) [0|0] "" Vector__XXX
 SG_ DM46_12FMI : 384|5@1+ (1,0) [0|0] "" Vector__XXX
 SG_ DM46_12SPN : 368|16@1+ (1,0) [0|0] "" Vector__XXX
 SG_ DM46_13OC : 424|7@1+ (1,0) [0|0] "" Vector__XXX
 SG_ DM46_13FMI : 416|5@1+ (1,0) [0|0] "" Vector__XXX
 SG_ DM46_13SPN : 400|16@1+ (1,0) [0|0] "" Vector__XXX
 SG_ DM46_14OC : 456|7@1+ (1,0) [0|0] "" Vector__XXX
 SG_ DM46_14FMI : 448|5@1+ (1,0) [0|0] "" Vector__XXX
 SG_ DM46_14SPN : 432|16@1+ (1,0) [0|0] "" Vector__XXX
 SG_ DM46_15OC : 488|7@1+ (1,0) [0|0] "" Vector__XXX
 SG_ DM46_15FMI : 480|5@1+ (1,0) [0|0] "" Vector__XXX
 SG_ DM46_15SPN : 464|16@1+ (1,0) [0|0] "" Vector__XXX
 SG_ DM46_16OC : 520|7@1+ (1,0) [0|0] "" Vector__XXX
 SG_ DM46_16FMI : 512|5@1+ (1,0) [0|0] "" Vector__XXX
 SG_ DM46_16SPN : 496|16@1+ (1,0) [0|0] "" Vector__XXX
 SG_ DM46_17OC : 552|7@1+ (1,0) [0|0] "" Vector__XXX
 SG_ DM46_17FMI : 544|5@1+ (1,0) [0|0] "" Vector__XXX
 SG_ DM46_17SPN : 528|16@1+ (1,0) [0|0] "" Vector__XXX
 SG_ DM46_18OC : 584|7@1+ (1,0) [0|0] "" Vector__XXX
 SG_ DM46_18FMI : 576|5@1+ (1,0) [0|0] "" Vector__XXX
 SG_ DM46_18SPN : 560|16@1+ (1,0) [0|0] "" Vector__XXX
 SG_ DM46_19OC : 616|7@1+ (1,0) [0|0] "" Vector__XXX
 SG_ DM46_19FMI : 608|5@1+ (1,0) [0|0] "" Vector__XXX
 SG_ DM46_19SPN : 592|16@1+ (1,0) [0|0] "" Vector__XXX
 SG_ DM46_19SPN_High : 613|3@1+ (65536,0) [0|0] "" Vector__XXX
 SG_ DM46_18SPN_High : 581|3@1+ (65536,0) [0|0] "" Vector__XXX
 SG_ DM46_17SPN_High : 549|3@1+ (65536,0) [0|0] "" Vector__XXX
 SG_ DM46_16SPN_High : 517|3@1+ (65536,0) [0|0] "" Vector__XXX
 SG_ DM46_15SPN_High : 485|3@1+ (65536,0) [0|0] "" Vector__XXX
 SG_ DM46_14SPN_High : 453|3@1+ (65536,0) [0|0] "" Vector__XXX
 SG_ DM46_13SPN_High : 421|3@1+ (65536,0) [0|0] "" Vector__XXX
 SG_ DM46_12SPN_High : 389|3@1+ (65536,0) [0|0] "" Vector__XXX
 SG_ DM46_11SPN_High : 357|3@1+ (65536,0) [0|0] "" Vector__XXX
 SG_ DM46_10SPN_High : 325|3@1+ (65536,0) [0|0] "" Vector__XXX
 SG_ DM46_09SPN_High : 293|3@1+ (65536,0) [0|0] "" Vector__XXX
 SG_ DM46_08SPN_High : 261|3@1+ (65536,0) [0|0] "" Vector__XXX
 SG_ DM46_07SPN_High : 229|3@1+ (65536,0) [0|0] "" Vector__XXX
 SG_ DM46_06SPN_High : 197|3@1+ (65536,0) [0|0] "" Vector__XXX
 SG_ DM46_05SPN_High : 165|3@1+ (65536,0) [0|0] "" Vector__XXX
 SG_ DM46_04SPN_High : 133|3@1+ (65536,0) [0|0] "" Vector__XXX
 SG_ DM46_03SPN_High : 101|3@1+ (65536,0) [0|0] "" Vector__XXX
 SG_ DM46_02SPN_High : 69|3@1+ (65536,0) [0|0] "" Vector__XXX
 SG_ DM46_01SPN_High : 37|3@1+ (65536,0) [0|0] "" Vector__XXX
 SG_ DM46_01CM : 47|1@1+ (1,0) [0|0] "" Vector__XXX
 SG_ DM46_02CM : 79|1@1+ (1,0) [0|0] "" Vector__XXX
 SG_ DM46_03CM : 111|1@1+ (1,0) [0|0] "" Vector__XXX
 SG_ DM46_04CM : 143|1@1+ (1,0) [0|0] "" Vector__XXX
 SG_ DM46_05CM : 175|1@1+ (1,0) [0|0] "" Vector__XXX
 SG_ DM46_06CM : 207|1@1+ (1,0) [0|0] "" Vector__XXX
 SG_ DM46_07CM : 239|1@1+ (1,0) [0|0] "" Vector__XXX
 SG_ DM46_08CM : 271|1@1+ (1,0) [0|0] "" Vector__XXX
 SG_ DM46_09CM : 303|1@1+ (1,0) [0|0] "" Vector__XXX
 SG_ DM46_10CM : 335|1@1+ (1,0) [0|0] "" Vector__XXX
 SG_ DM46_11CM : 367|1@1+ (1,0) [0|0] "" Vector__XXX
 SG_ DM46_12CM : 399|1@1+ (1,0) [0|0] "" Vector__XXX
 SG_ DM46_13CM : 431|1@1+ (1,0) [0|0] "" Vector__XXX
 SG_ DM46_14CM : 463|1@1+ (1,0) [0|0] "" Vector__XXX
 SG_ DM46_15CM : 495|1@1+ (1,0) [0|0] "" Vector__XXX
 SG_ DM46_16CM : 527|1@1+ (1,0) [0|0] "" Vector__XXX
 SG_ DM46_17CM : 559|1@1+ (1,0) [0|0] "" Vector__XXX
 SG_ DM46_18CM : 591|1@1+ (1,0) [0|0] "" Vector__XXX
 SG_ DM46_19CM : 623|1@1+ (1,0) [0|0] "" Vector__XXX

BO_ 2566740990 DM45: 78 Vector__XXX
 SG_ FlashRedStopLamp : 12|2@1+ (1,0) [0|3] "" Vector__XXX
 SG_ FlashProtectLamp : 8|2@1+ (1,0) [0|3] "" Vector__XXX
 SG_ FlashMalfuncIndicatorLamp : 14|2@1+ (1,0) [0|3] "" Vector__XXX
 SG_ FlashAmberWarningLamp : 10|2@1+ (1,0) [0|3] "" Vector__XXX
 SG_ MalfunctionIndicatorLampStatus : 6|2@1+ (1,0) [0|3] "" Vector__XXX
 SG_ AmberWarningLampStatus : 2|2@1+ (1,0) [0|3] "" Vector__XXX
 SG_ RedStopLampStatus : 4|2@1+ (1,0) [0|3] "" Vector__XXX
 SG_ ProtectLampStatus : 0|2@1+ (1,0) [0|3] "" Vector__XXX
 SG_ DM45_01OC : 40|7@1+ (1,0) [0|0] "" Vector__XXX
 SG_ DM45_01FMI : 32|5@1+ (1,0) [0|0] "" Vector__XXX
 SG_ DM45_01SPN : 16|16@1+ (1,0) [0|0] "" Vector__XXX
 SG_ DM45_02OC : 72|7@1+ (1,0) [0|0] "" Vector__XXX
 SG_ DM45_02FMI : 64|5@1+ (1,0) [0|0] "" Vector__XXX
 SG_ DM45_02SPN : 48|16@1+ (1,0) [0|0] "" Vector__XXX
 SG_ DM45_03OC : 104|7@1+ (1,0) [0|0] "" Vector__XXX
 SG_ DM45_03FMI : 96|5@1+ (1,0) [0|0] "" Vector__XXX
 SG_ DM45_03SPN : 80|16@1+ (1,0) [0|0] "" Vector__XXX
 SG_ DM45_04OC : 136|7@1+ (1,0) [0|0] "" Vector__XXX
 SG_ DM45_04FMI : 128|5@1+ (1,0) [0|0] "" Vector__XXX
 SG_ DM45_04SPN : 112|16@1+ (1,0) [0|0] "" Vector__XXX
 SG_ DM45_05OC : 168|7@1+ (1,0) [0|0] "" Vector__XXX
 SG_ DM45_05FMI : 160|5@1+ (1,0) [0|0] "" Vector__XXX
 SG_ DM45_05SPN : 144|16@1+ (1,0) [0|0] "" Vector__XXX
 SG_ DM45_06OC : 200|7@1+ (1,0) [0|0] "" Vector__XXX
 SG_ DM45_06FMI : 192|5@1+ (1,0) [0|0] "" Vector__XXX
 SG_ DM45_06SPN : 176|16@1+ (1,0) [0|0] "" Vector__XXX
 SG_ DM45_07OC : 232|7@1+ (1,0) [0|0] "" Vector__XXX
 SG_ DM45_07FMI : 224|5@1+ (1,0) [0|0] "" Vector__XXX
 SG_ DM45_07SPN : 208|16@1+ (1,0) [0|0] "" Vector__XXX
 SG_ DM45_08OC : 264|7@1+ (1,0) [0|0] "" Vector__XXX
 SG_ DM45_08FMI : 256|5@1+ (1,0) [0|0] "" Vector__XXX
 SG_ DM45_08SPN : 240|16@1+ (1,0) [0|0] "" Vector__XXX
 SG_ DM45_09OC : 296|7@1+ (1,0) [0|0] "" Vector__XXX
 SG_ DM45_09FMI : 288|5@1+ (1,0) [0|0] "" Vector__XXX
 SG_ DM45_09SPN : 272|16@1+ (1,0) [0|0] "" Vector__XXX
 SG_ DM45_10OC : 328|7@1+ (1,0) [0|0] "" Vector__XXX
 SG_ DM45_10FMI : 320|5@1+ (1,0) [0|0] "" Vector__XXX
 SG_ DM45_10SPN : 304|16@1+ (1,0) [0|0] "" Vector__XXX
 SG_ DM45_11OC : 360|7@1+ (1,0) [0|0] "" Vector__XXX
 SG_ DM45_11FMI : 352|5@1+ (1,0) [0|0] "" Vector__XXX
 SG_ DM45_11SPN : 336|16@1+ (1,0) [0|0] "" Vector__XXX
 SG_ DM45_12OC : 392|7@1+ (1,0) [0|0] "" Vector__XXX
 SG_ DM45_12FMI : 384|5@1+ (1,0) [0|0] "" Vector__XXX
 SG_ DM45_12SPN : 368|16@1+ (1,0) [0|0] "" Vector__XXX
 SG_ DM45_13OC : 424|7@1+ (1,0) [0|0] "" Vector__XXX
 SG_ DM45_13FMI : 416|5@1+ (1,0) [0|0] "" Vector__XXX
 SG_ DM45_13SPN : 400|16@1+ (1,0) [0|0] "" Vector__XXX
 SG_ DM45_14OC : 456|7@1+ (1,0) [0|0] "" Vector__XXX
 SG_ DM45_14FMI : 448|5@1+ (1,0) [0|0] "" Vector__XXX
 SG_ DM45_14SPN : 432|16@1+ (1,0) [0|0] "" Vector__XXX
 SG_ DM45_15OC : 488|7@1+ (1,0) [0|0] "" Vector__XXX
 SG_ DM45_15FMI : 480|5@1+ (1,0) [0|0] "" Vector__XXX
 SG_ DM45_15SPN : 464|16@1+ (1,0) [0|0] "" Vector__XXX
 SG_ DM45_16OC : 520|7@1+ (1,0) [0|0] "" Vector__XXX
 SG_ DM45_16FMI : 512|5@1+ (1,0) [0|0] "" Vector__XXX
 SG_ DM45_16SPN : 496|16@1+ (1,0) [0|0] "" Vector__XXX
 SG_ DM45_17OC : 552|7@1+ (1,0) [0|0] "" Vector__XXX
 SG_ DM45_17FMI : 544|5@1+ (1,0) [0|0] "" Vector__XXX
 SG_ DM45_17SPN : 528|16@1+ (1,0) [0|0] "" Vector__XXX
 SG_ DM45_18OC : 584|7@1+ (1,0) [0|0] "" Vector__XXX
 SG_ DM45_18FMI : 576|5@1+ (1,0) [0|0] "" Vector__XXX
 SG_ DM45_18SPN : 560|16@1+ (1,0) [0|0] "" Vector__XXX
 SG_ DM45_19OC : 616|7@1+ (1,0) [0|0] "" Vector__XXX
 SG_ DM45_19FMI : 608|5@1+ (1,0) [0|0] "" Vector__XXX
 SG_ DM45_19SPN : 592|16@1+ (1,0) [0|0] "" Vector__XXX
 SG_ DM45_19SPN_High : 613|3@1+ (65536,0) [0|0] "" Vector__XXX
 SG_ DM45_18SPN_High : 581|3@1+ (65536,0) [0|0] "" Vector__XXX
 SG_ DM45_17SPN_High : 549|3@1+ (65536,0) [0|0] "" Vector__XXX
 SG_ DM45_16SPN_High : 517|3@1+ (65536,0) [0|0] "" Vector__XXX
 SG_ DM45_15SPN_High : 485|3@1+ (65536,0) [0|0] "" Vector__XXX
 SG_ DM45_14SPN_High : 453|3@1+ (65536,0) [0|0] "" Vector__XXX
 SG_ DM45_13SPN_High : 421|3@1+ (65536,0) [0|0] "" Vector__XXX
 SG_ DM45_12SPN_High : 389|3@1+ (65536,0) [0|0] "" Vector__XXX
 SG_ DM45_11SPN_High : 357|3@1+ (65536,0) [0|0] "" Vector__XXX
 SG_ DM45_10SPN_High : 325|3@1+ (65536,0) [0|0] "" Vector__XXX
 SG_ DM45_09SPN_High : 293|3@1+ (65536,0) [0|0] "" Vector__XXX
 SG_ DM45_08SPN_High : 261|3@1+ (65536,0) [0|0] "" Vector__XXX
 SG_ DM45_07SPN_High : 229|3@1+ (65536,0) [0|0] "" Vector__XXX
 SG_ DM45_06SPN_High : 197|3@1+ (65536,0) [0|0] "" Vector__XXX
 SG_ DM45_05SPN_High : 165|3@1+ (65536,0) [0|0] "" Vector__XXX
 SG_ DM45_04SPN_High : 133|3@1+ (65536,0) [0|0] "" Vector__XXX
 SG_ DM45_03SPN_High : 101|3@1+ (65536,0) [0|0] "" Vector__XXX
 SG_ DM45_02SPN_High : 69|3@1+ (65536,0) [0|0] "" Vector__XXX
 SG_ DM45_01SPN_High : 37|3@1+ (65536,0) [0|0] "" Vector__XXX
 SG_ DM45_01CM : 47|1@1+ (1,0) [0|0] "" Vector__XXX
 SG_ DM45_02CM : 79|1@1+ (1,0) [0|0] "" Vector__XXX
 SG_ DM45_03CM : 111|1@1+ (1,0) [0|0] "" Vector__XXX
 SG_ DM45_04CM : 143|1@1+ (1,0) [0|0] "" Vector__XXX
 SG_ DM45_05CM : 175|1@1+ (1,0) [0|0] "" Vector__XXX
 SG_ DM45_06CM : 207|1@1+ (1,0) [0|0] "" Vector__XXX
 SG_ DM45_07CM : 239|1@1+ (1,0) [0|0] "" Vector__XXX
 SG_ DM45_08CM : 271|1@1+ (1,0) [0|0] "" Vector__XXX
 SG_ DM45_09CM : 303|1@1+ (1,0) [0|0] "" Vector__XXX
 SG_ DM45_10CM : 335|1@1+ (1,0) [0|0] "" Vector__XXX
 SG_ DM45_11CM : 367|1@1+ (1,0) [0|0] "" Vector__XXX
 SG_ DM45_12CM : 399|1@1+ (1,0) [0|0] "" Vector__XXX
 SG_ DM45_13CM : 431|1@1+ (1,0) [0|0] "" Vector__XXX
 SG_ DM45_14CM : 463|1@1+ (1,0) [0|0] "" Vector__XXX
 SG_ DM45_15CM : 495|1@1+ (1,0) [0|0] "" Vector__XXX
 SG_ DM45_16CM : 527|1@1+ (1,0) [0|0] "" Vector__XXX
 SG_ DM45_17CM : 559|1@1+ (1,0) [0|0] "" Vector__XXX
 SG_ DM45_18CM : 591|1@1+ (1,0) [0|0] "" Vector__XXX
 SG_ DM45_19CM : 623|1@1+ (1,0) [0|0] "" Vector__XXX

BO_ 2566741246 DM44: 78 Vector__XXX
 SG_ FlashRedStopLamp : 12|2@1+ (1,0) [0|3] "" Vector__XXX
 SG_ FlashProtectLamp : 8|2@1+ (1,0) [0|3] "" Vector__XXX
 SG_ FlashMalfuncIndicatorLamp : 14|2@1+ (1,0) [0|3] "" Vector__XXX
 SG_ FlashAmberWarningLamp : 10|2@1+ (1,0) [0|3] "" Vector__XXX
 SG_ MalfunctionIndicatorLampStatus : 6|2@1+ (1,0) [0|3] "" Vector__XXX
 SG_ AmberWarningLampStatus : 2|2@1+ (1,0) [0|3] "" Vector__XXX
 SG_ RedStopLampStatus : 4|2@1+ (1,0) [0|3] "" Vector__XXX
 SG_ ProtectLampStatus : 0|2@1+ (1,0) [0|3] "" Vector__XXX
 SG_ DM44_01OC : 40|7@1+ (1,0) [0|0] "" Vector__XXX
 SG_ DM44_01FMI : 32|5@1+ (1,0) [0|0] "" Vector__XXX
 SG_ DM44_01SPN : 16|16@1+ (1,0) [0|0] "" Vector__XXX
 SG_ DM44_02OC : 72|7@1+ (1,0) [0|0] "" Vector__XXX
 SG_ DM44_02FMI : 64|5@1+ (1,0) [0|0] "" Vector__XXX
 SG_ DM44_02SPN : 48|16@1+ (1,0) [0|0] "" Vector__XXX
 SG_ DM44_03OC : 104|7@1+ (1,0) [0|0] "" Vector__XXX
 SG_ DM44_03FMI : 96|5@1+ (1,0) [0|0] "" Vector__XXX
 SG_ DM44_03SPN : 80|16@1+ (1,0) [0|0] "" Vector__XXX
 SG_ DM44_04OC : 136|7@1+ (1,0) [0|0] "" Vector__XXX
 SG_ DM44_04FMI : 128|5@1+ (1,0) [0|0] "" Vector__XXX
 SG_ DM44_04SPN : 112|16@1+ (1,0) [0|0] "" Vector__XXX
 SG_ DM44_05OC : 168|7@1+ (1,0) [0|0] "" Vector__XXX
 SG_ DM44_05FMI : 160|5@1+ (1,0) [0|0] "" Vector__XXX
 SG_ DM44_05SPN : 144|16@1+ (1,0) [0|0] "" Vector__XXX
 SG_ DM44_06OC : 200|7@1+ (1,0) [0|0] "" Vector__XXX
 SG_ DM44_06FMI : 192|5@1+ (1,0) [0|0] "" Vector__XXX
 SG_ DM44_06SPN : 176|16@1+ (1,0) [0|0] "" Vector__XXX
 SG_ DM44_07OC : 232|7@1+ (1,0) [0|0] "" Vector__XXX
 SG_ DM44_07FMI : 224|5@1+ (1,0) [0|0] "" Vector__XXX
 SG_ DM44_07SPN : 208|16@1+ (1,0) [0|0] "" Vector__XXX
 SG_ DM44_08OC : 264|7@1+ (1,0) [0|0] "" Vector__XXX
 SG_ DM44_08FMI : 256|5@1+ (1,0) [0|0] "" Vector__XXX
 SG_ DM44_08SPN : 240|16@1+ (1,0) [0|0] "" Vector__XXX
 SG_ DM44_09OC : 296|7@1+ (1,0) [0|0] "" Vector__XXX
 SG_ DM44_09FMI : 288|5@1+ (1,0) [0|0] "" Vector__XXX
 SG_ DM44_09SPN : 272|16@1+ (1,0) [0|0] "" Vector__XXX
 SG_ DM44_10OC : 328|7@1+ (1,0) [0|0] "" Vector__XXX
 SG_ DM44_10FMI : 320|5@1+ (1,0) [0|0] "" Vector__XXX
 SG_ DM44_10SPN : 304|16@1+ (1,0) [0|0] "" Vector__XXX
 SG_ DM44_11OC : 360|7@1+ (1,0) [0|0] "" Vector__XXX
 SG_ DM44_11FMI : 352|5@1+ (1,0) [0|0] "" Vector__XXX
 SG_ DM44_11SPN : 336|16@1+ (1,0) [0|0] "" Vector__XXX
 SG_ DM44_12OC : 392|7@1+ (1,0) [0|0] "" Vector__XXX
 SG_ DM44_12FMI : 384|5@1+ (1,0) [0|0] "" Vector__XXX
 SG_ DM44_12SPN : 368|16@1+ (1,0) [0|0] "" Vector__XXX
 SG_ DM44_13OC : 424|7@1+ (1,0) [0|0] "" Vector__XXX
 SG_ DM44_13FMI : 416|5@1+ (1,0) [0|0] "" Vector__XXX
 SG_ DM44_13SPN : 400|16@1+ (1,0) [0|0] "" Vector__XXX
 SG_ DM44_14OC : 456|7@1+ (1,0) [0|0] "" Vector__XXX
 SG_ DM44_14FMI : 448|5@1+ (1,0) [0|0] "" Vector__XXX
 SG_ DM44_14SPN : 432|16@1+ (1,0) [0|0] "" Vector__XXX
 SG_ DM44_15OC : 488|7@1+ (1,0) [0|0] "" Vector__XXX
 SG_ DM44_15FMI : 480|5@1+ (1,0) [0|0] "" Vector__XXX
 SG_ DM44_15SPN : 464|16@1+ (1,0) [0|0] "" Vector__XXX
 SG_ DM44_16OC : 520|7@1+ (1,0) [0|0] "" Vector__XXX
 SG_ DM44_16FMI : 512|5@1+ (1,0) [0|0] "" Vector__XXX
 SG_ DM44_16SPN : 496|16@1+ (1,0) [0|0] "" Vector__XXX
 SG_ DM44_17OC : 552|7@1+ (1,0) [0|0] "" Vector__XXX
 SG_ DM44_17FMI : 544|5@1+ (1,0) [0|0] "" Vector__XXX
 SG_ DM44_17SPN : 528|16@1+ (1,0) [0|0] "" Vector__XXX
 SG_ DM44_18OC : 584|7@1+ (1,0) [0|0] "" Vector__XXX
 SG_ DM44_18FMI : 576|5@1+ (1,0) [0|0] "" Vector__XXX
 SG_ DM44_18SPN : 560|16@1+ (1,0) [0|0] "" Vector__XXX
 SG_ DM44_19OC : 616|7@1+ (1,0) [0|0] "" Vector__XXX
 SG_ DM44_19FMI : 608|5@1+ (1,0) [0|0] "" Vector__XXX
 SG_ DM44_19SPN : 592|16@1+ (1,0) [0|0] "" Vector__XXX
 SG_ DM44_19SPN_High : 613|3@1+ (65536,0) [0|0] "" Vector__XXX
 SG_ DM44_18SPN_High : 581|3@1+ (65536,0) [0|0] "" Vector__XXX
 SG_ DM44_17SPN_High : 549|3@1+ (65536,0) [0|0] "" Vector__XXX
 SG_ DM44_16SPN_High : 517|3@1+ (65536,0) [0|0] "" Vector__XXX
 SG_ DM44_15SPN_High : 485|3@1+ (65536,0) [0|0] "" Vector__XXX
 SG_ DM44_14SPN_High : 453|3@1+ (65536,0) [0|0] "" Vector__XXX
 SG_ DM44_13SPN_High : 421|3@1+ (65536,0) [0|0] "" Vector__XXX
 SG_ DM44_12SPN_High : 389|3@1+ (65536,0) [0|0] "" Vector__XXX
 SG_ DM44_11SPN_High : 357|3@1+ (65536,0) [0|0] "" Vector__XXX
 SG_ DM44_10SPN_High : 325|3@1+ (65536,0) [0|0] "" Vector__XXX
 SG_ DM44_09SPN_High : 293|3@1+ (65536,0) [0|0] "" Vector__XXX
 SG_ DM44_08SPN_High : 261|3@1+ (65536,0) [0|0] "" Vector__XXX
 SG_ DM44_07SPN_High : 229|3@1+ (65536,0) [0|0] "" Vector__XXX
 SG_ DM44_06SPN_High : 197|3@1+ (65536,0) [0|0] "" Vector__XXX
 SG_ DM44_05SPN_High : 165|3@1+ (65536,0) [0|0] "" Vector__XXX
 SG_ DM44_04SPN_High : 133|3@1+ (65536,0) [0|0] "" Vector__XXX
 SG_ DM44_03SPN_High : 101|3@1+ (65536,0) [0|0] "" Vector__XXX
 SG_ DM44_02SPN_High : 69|3@1+ (65536,0) [0|0] "" Vector__XXX
 SG_ DM44_01SPN_High : 37|3@1+ (65536,0) [0|0] "" Vector__XXX
 SG_ DM44_01CM : 47|1@1+ (1,0) [0|0] "" Vector__XXX
 SG_ DM44_02CM : 79|1@1+ (1,0) [0|0] "" Vector__XXX
 SG_ DM44_03CM : 111|1@1+ (1,0) [0|0] "" Vector__XXX
 SG_ DM44_04CM : 143|1@1+ (1,0) [0|0] "" Vector__XXX
 SG_ DM44_05CM : 175|1@1+ (1,0) [0|0] "" Vector__XXX
 SG_ DM44_06CM : 207|1@1+ (1,0) [0|0] "" Vector__XXX
 SG_ DM44_07CM : 239|1@1+ (1,0) [0|0] "" Vector__XXX
 SG_ DM44_08CM : 271|1@1+ (1,0) [0|0] "" Vector__XXX
 SG_ DM44_09CM : 303|1@1+ (1,0) [0|0] "" Vector__XXX
 SG_ DM44_10CM : 335|1@1+ (1,0) [0|0] "" Vector__XXX
 SG_ DM44_11CM : 367|1@1+ (1,0) [0|0] "" Vector__XXX
 SG_ DM44_12CM : 399|1@1+ (1,0) [0|0] "" Vector__XXX
 SG_ DM44_13CM : 431|1@1+ (1,0) [0|0] "" Vector__XXX
 SG_ DM44_14CM : 463|1@1+ (1,0) [0|0] "" Vector__XXX
 SG_ DM44_15CM : 495|1@1+ (1,0) [0|0] "" Vector__XXX
 SG_ DM44_16CM : 527|1@1+ (1,0) [0|0] "" Vector__XXX
 SG_ DM44_17CM : 559|1@1+ (1,0) [0|0] "" Vector__XXX
 SG_ DM44_18CM : 591|1@1+ (1,0) [0|0] "" Vector__XXX
 SG_ DM44_19CM : 623|1@1+ (1,0) [0|0] "" Vector__XXX

BO_ 2566741502 DM43: 78 Vector__XXX
 SG_ FlashRedStopLamp : 12|2@1+ (1,0) [0|3] "" Vector__XXX
 SG_ FlashProtectLamp : 8|2@1+ (1,0) [0|3] "" Vector__XXX
 SG_ FlashMalfuncIndicatorLamp : 14|2@1+ (1,0) [0|3] "" Vector__XXX
 SG_ FlashAmberWarningLamp : 10|2@1+ (1,0) [0|3] "" Vector__XXX
 SG_ MalfunctionIndicatorLampStatus : 6|2@1+ (1,0) [0|3] "" Vector__XXX
 SG_ AmberWarningLampStatus : 2|2@1+ (1,0) [0|3] "" Vector__XXX
 SG_ RedStopLampStatus : 4|2@1+ (1,0) [0|3] "" Vector__XXX
 SG_ ProtectLampStatus : 0|2@1+ (1,0) [0|3] "" Vector__XXX
 SG_ DM43_01OC : 40|7@1+ (1,0) [0|0] "" Vector__XXX
 SG_ DM43_01FMI : 32|5@1+ (1,0) [0|0] "" Vector__XXX
 SG_ DM43_01SPN : 16|16@1+ (1,0) [0|0] "" Vector__XXX
 SG_ DM43_02OC : 72|7@1+ (1,0) [0|0] "" Vector__XXX
 SG_ DM43_02FMI : 64|5@1+ (1,0) [0|0] "" Vector__XXX
 SG_ DM43_02SPN : 48|16@1+ (1,0) [0|0] "" Vector__XXX
 SG_ DM43_03OC : 104|7@1+ (1,0) [0|0] "" Vector__XXX
 SG_ DM43_03FMI : 96|5@1+ (1,0) [0|0] "" Vector__XXX
 SG_ DM43_03SPN : 80|16@1+ (1,0) [0|0] "" Vector__XXX
 SG_ DM43_04OC : 136|7@1+ (1,0) [0|0] "" Vector__XXX
 SG_ DM43_04FMI : 128|5@1+ (1,0) [0|0] "" Vector__XXX
 SG_ DM43_04SPN : 112|16@1+ (1,0) [0|0] "" Vector__XXX
 SG_ DM43_05OC : 168|7@1+ (1,0) [0|0] "" Vector__XXX
 SG_ DM43_05FMI : 160|5@1+ (1,0) [0|0] "" Vector__XXX
 SG_ DM43_05SPN : 144|16@1+ (1,0) [0|0] "" Vector__XXX
 SG_ DM43_06OC : 200|7@1+ (1,0) [0|0] "" Vector__XXX
 SG_ DM43_06FMI : 192|5@1+ (1,0) [0|0] "" Vector__XXX
 SG_ DM43_06SPN : 176|16@1+ (1,0) [0|0] "" Vector__XXX
 SG_ DM43_07OC : 232|7@1+ (1,0) [0|0] "" Vector__XXX
 SG_ DM43_07FMI : 224|5@1+ (1,0) [0|0] "" Vector__XXX
 SG_ DM43_07SPN : 208|16@1+ (1,0) [0|0] "" Vector__XXX
 SG_ DM43_08OC : 264|7@1+ (1,0) [0|0] "" Vector__XXX
 SG_ DM43_08FMI : 256|5@1+ (1,0) [0|0] "" Vector__XXX
 SG_ DM43_08SPN : 240|16@1+ (1,0) [0|0] "" Vector__XXX
 SG_ DM43_09OC : 296|7@1+ (1,0) [0|0] "" Vector__XXX
 SG_ DM43_09FMI : 288|5@1+ (1,0) [0|0] "" Vector__XXX
 SG_ DM43_09SPN : 272|16@1+ (1,0) [0|0] "" Vector__XXX
 SG_ DM43_10OC : 328|7@1+ (1,0) [0|0] "" Vector__XXX
 SG_ DM43_10FMI : 320|5@1+ (1,0) [0|0] "" Vector__XXX
 SG_ DM43_10SPN : 304|16@1+ (1,0) [0|0] "" Vector__XXX
 SG_ DM43_11OC : 360|7@1+ (1,0) [0|0] "" Vector__XXX
 SG_ DM43_11FMI : 352|5@1+ (1,0) [0|0] "" Vector__XXX
 SG_ DM43_11SPN : 336|16@1+ (1,0) [0|0] "" Vector__XXX
 SG_ DM43_12OC : 392|7@1+ (1,0) [0|0] "" Vector__XXX
 SG_ DM43_12FMI : 384|5@1+ (1,0) [0|0] "" Vector__XXX
 SG_ DM43_12SPN : 368|16@1+ (1,0) [0|0] "" Vector__XXX
 SG_ DM43_13OC : 424|7@1+ (1,0) [0|0] "" Vector__XXX
 SG_ DM43_13FMI : 416|5@1+ (1,0) [0|0] "" Vector__XXX
 SG_ DM43_13SPN : 400|16@1+ (1,0) [0|0] "" Vector__XXX
 SG_ DM43_14OC : 456|7@1+ (1,0) [0|0] "" Vector__XXX
 SG_ DM43_14FMI : 448|5@1+ (1,0) [0|0] "" Vector__XXX
 SG_ DM43_14SPN : 432|16@1+ (1,0) [0|0] "" Vector__XXX
 SG_ DM43_15OC : 488|7@1+ (1,0) [0|0] "" Vector__XXX
 SG_ DM43_15FMI : 480|5@1+ (1,0) [0|0] "" Vector__XXX
 SG_ DM43_15SPN : 464|16@1+ (1,0) [0|0] "" Vector__XXX
 SG_ DM43_16OC : 520|7@1+ (1,0) [0|0] "" Vector__XXX
 SG_ DM43_16FMI : 512|5@1+ (1,0) [0|0] "" Vector__XXX
 SG_ DM43_16SPN : 496|16@1+ (1,0) [0|0] "" Vector__XXX
 SG_ DM43_17OC : 552|7@1+ (1,0) [0|0] "" Vector__XXX
 SG_ DM43_17FMI : 544|5@1+ (1,0) [0|0] "" Vector__XXX
 SG_ DM43_17SPN : 528|16@1+ (1,0) [0|0] "" Vector__XXX
 SG_ DM43_18OC : 584|7@1+ (1,0) [0|0] "" Vector__XXX
 SG_ DM43_18FMI : 576|5@1+ (1,0) [0|0] "" Vector__XXX
 SG_ DM43_18SPN : 560|16@1+ (1,0) [0|0] "" Vector__XXX
 SG_ DM43_19OC : 616|7@1+ (1,0) [0|0] "" Vector__XXX
 SG_ DM43_19FMI : 608|5@1+ (1,0) [0|0] "" Vector__XXX
 SG_ DM43_19SPN : 592|16@1+ (1,0) [0|0] "" Vector__XXX
 SG_ DM43_19SPN_High : 613|3@1+ (65536,0) [0|0] "" Vector__XXX
 SG_ DM43_18SPN_High : 581|3@1+ (65536,0) [0|0] "" Vector__XXX
 SG_ DM43_17SPN_High : 549|3@1+ (65536,0) [0|0] "" Vector__XXX
 SG_ DM43_16SPN_High : 517|3@1+ (65536,0) [0|0] "" Vector__XXX
 SG_ DM43_15SPN_High : 485|3@1+ (65536,0) [0|0] "" Vector__XXX
 SG_ DM43_14SPN_High : 453|3@1+ (65536,0) [0|0] "" Vector__XXX
 SG_ DM43_13SPN_High : 421|3@1+ (65536,0) [0|0] "" Vector__XXX
 SG_ DM43_12SPN_High : 389|3@1+ (65536,0) [0|0] "" Vector__XXX
 SG_ DM43_11SPN_High : 357|3@1+ (65536,0) [0|0] "" Vector__XXX
 SG_ DM43_10SPN_High : 325|3@1+ (65536,0) [0|0] "" Vector__XXX
 SG_ DM43_09SPN_High : 293|3@1+ (65536,0) [0|0] "" Vector__XXX
 SG_ DM43_08SPN_High : 261|3@1+ (65536,0) [0|0] "" Vector__XXX
 SG_ DM43_07SPN_High : 229|3@1+ (65536,0) [0|0] "" Vector__XXX
 SG_ DM43_06SPN_High : 197|3@1+ (65536,0) [0|0] "" Vector__XXX
 SG_ DM43_05SPN_High : 165|3@1+ (65536,0) [0|0] "" Vector__XXX
 SG_ DM43_04SPN_High : 133|3@1+ (65536,0) [0|0] "" Vector__XXX
 SG_ DM43_03SPN_High : 101|3@1+ (65536,0) [0|0] "" Vector__XXX
 SG_ DM43_02SPN_High : 69|3@1+ (65536,0) [0|0] "" Vector__XXX
 SG_ DM43_01SPN_High : 37|3@1+ (65536,0) [0|0] "" Vector__XXX
 SG_ DM43_01CM : 47|1@1+ (1,0) [0|0] "" Vector__XXX
 SG_ DM43_02CM : 79|1@1+ (1,0) [0|0] "" Vector__XXX
 SG_ DM43_03CM : 111|1@1+ (1,0) [0|0] "" Vector__XXX
 SG_ DM43_04CM : 143|1@1+ (1,0) [0|0] "" Vector__XXX
 SG_ DM43_05CM : 175|1@1+ (1,0) [0|0] "" Vector__XXX
 SG_ DM43_06CM : 207|1@1+ (1,0) [0|0] "" Vector__XXX
 SG_ DM43_07CM : 239|1@1+ (1,0) [0|0] "" Vector__XXX
 SG_ DM43_08CM : 271|1@1+ (1,0) [0|0] "" Vector__XXX
 SG_ DM43_09CM : 303|1@1+ (1,0) [0|0] "" Vector__XXX
 SG_ DM43_10CM : 335|1@1+ (1,0) [0|0] "" Vector__XXX
 SG_ DM43_11CM : 367|1@1+ (1,0) [0|0] "" Vector__XXX
 SG_ DM43_12CM : 399|1@1+ (1,0) [0|0] "" Vector__XXX
 SG_ DM43_13CM : 431|1@1+ (1,0) [0|0] "" Vector__XXX
 SG_ DM43_14CM : 463|1@1+ (1,0) [0|0] "" Vector__XXX
 SG_ DM43_15CM : 495|1@1+ (1,0) [0|0] "" Vector__XXX
 SG_ DM43_16CM : 527|1@1+ (1,0) [0|0] "" Vector__XXX
 SG_ DM43_17CM : 559|1@1+ (1,0) [0|0] "" Vector__XXX
 SG_ DM43_18CM : 591|1@1+ (1,0) [0|0] "" Vector__XXX
 SG_ DM43_19CM : 623|1@1+ (1,0) [0|0] "" Vector__XXX

BO_ 2566741758 DM42: 78 Vector__XXX
 SG_ FlashRedStopLamp : 12|2@1+ (1,0) [0|3] "" Vector__XXX
 SG_ FlashProtectLamp : 8|2@1+ (1,0) [0|3] "" Vector__XXX
 SG_ FlashMalfuncIndicatorLamp : 14|2@1+ (1,0) [0|3] "" Vector__XXX
 SG_ FlashAmberWarningLamp : 10|2@1+ (1,0) [0|3] "" Vector__XXX
 SG_ MalfunctionIndicatorLampStatus : 6|2@1+ (1,0) [0|3] "" Vector__XXX
 SG_ AmberWarningLampStatus : 2|2@1+ (1,0) [0|3] "" Vector__XXX
 SG_ RedStopLampStatus : 4|2@1+ (1,0) [0|3] "" Vector__XXX
 SG_ ProtectLampStatus : 0|2@1+ (1,0) [0|3] "" Vector__XXX
 SG_ DM42_01OC : 40|7@1+ (1,0) [0|0] "" Vector__XXX
 SG_ DM42_01FMI : 32|5@1+ (1,0) [0|0] "" Vector__XXX
 SG_ DM42_01SPN : 16|16@1+ (1,0) [0|0] "" Vector__XXX
 SG_ DM42_02OC : 72|7@1+ (1,0) [0|0] "" Vector__XXX
 SG_ DM42_02FMI : 64|5@1+ (1,0) [0|0] "" Vector__XXX
 SG_ DM42_02SPN : 48|16@1+ (1,0) [0|0] "" Vector__XXX
 SG_ DM42_03OC : 104|7@1+ (1,0) [0|0] "" Vector__XXX
 SG_ DM42_03FMI : 96|5@1+ (1,0) [0|0] "" Vector__XXX
 SG_ DM42_03SPN : 80|16@1+ (1,0) [0|0] "" Vector__XXX
 SG_ DM42_04OC : 136|7@1+ (1,0) [0|0] "" Vector__XXX
 SG_ DM42_04FMI : 128|5@1+ (1,0) [0|0] "" Vector__XXX
 SG_ DM42_04SPN : 112|16@1+ (1,0) [0|0] "" Vector__XXX
 SG_ DM42_05OC : 168|7@1+ (1,0) [0|0] "" Vector__XXX
 SG_ DM42_05FMI : 160|5@1+ (1,0) [0|0] "" Vector__XXX
 SG_ DM42_05SPN : 144|16@1+ (1,0) [0|0] "" Vector__XXX
 SG_ DM42_06OC : 200|7@1+ (1,0) [0|0] "" Vector__XXX
 SG_ DM42_06FMI : 192|5@1+ (1,0) [0|0] "" Vector__XXX
 SG_ DM42_06SPN : 176|16@1+ (1,0) [0|0] "" Vector__XXX
 SG_ DM42_07OC : 232|7@1+ (1,0) [0|0] "" Vector__XXX
 SG_ DM42_07FMI : 224|5@1+ (1,0) [0|0] "" Vector__XXX
 SG_ DM42_07SPN : 208|16@1+ (1,0) [0|0] "" Vector__XXX
 SG_ DM42_08OC : 264|7@1+ (1,0) [0|0] "" Vector__XXX
 SG_ DM42_08FMI : 256|5@1+ (1,0) [0|0] "" Vector__XXX
 SG_ DM42_08SPN : 240|16@1+ (1,0) [0|0] "" Vector__XXX
 SG_ DM42_09OC : 296|7@1+ (1,0) [0|0] "" Vector__XXX
 SG_ DM42_09FMI : 288|5@1+ (1,0) [0|0] "" Vector__XXX
 SG_ DM42_09SPN : 272|16@1+ (1,0) [0|0] "" Vector__XXX
 SG_ DM42_10OC : 328|7@1+ (1,0) [0|0] "" Vector__XXX
 SG_ DM42_10FMI : 320|5@1+ (1,0) [0|0] "" Vector__XXX
 SG_ DM42_10SPN : 304|16@1+ (1,0) [0|0] "" Vector__XXX
 SG_ DM42_11OC : 360|7@1+ (1,0) [0|0] "" Vector__XXX
 SG_ DM42_11FMI : 352|5@1+ (1,0) [0|0] "" Vector__XXX
 SG_ DM42_11SPN : 336|16@1+ (1,0) [0|0] "" Vector__XXX
 SG_ DM42_12OC : 392|7@1+ (1,0) [0|0] "" Vector__XXX
 SG_ DM42_12FMI : 384|5@1+ (1,0) [0|0] "" Vector__XXX
 SG_ DM42_12SPN : 368|16@1+ (1,0) [0|0] "" Vector__XXX
 SG_ DM42_13OC : 424|7@1+ (1,0) [0|0] "" Vector__XXX
 SG_ DM42_13FMI : 416|5@1+ (1,0) [0|0] "" Vector__XXX
 SG_ DM42_13SPN : 400|16@1+ (1,0) [0|0] "" Vector__XXX
 SG_ DM42_14OC : 456|7@1+ (1,0) [0|0] "" Vector__XXX
 SG_ DM42_14FMI : 448|5@1+ (1,0) [0|0] "" Vector__XXX
 SG_ DM42_14SPN : 432|16@1+ (1,0) [0|0] "" Vector__XXX
 SG_ DM42_15OC : 488|7@1+ (1,0) [0|0] "" Vector__XXX
 SG_ DM42_15FMI : 480|5@1+ (1,0) [0|0] "" Vector__XXX
 SG_ DM42_15SPN : 464|16@1+ (1,0) [0|0] "" Vector__XXX
 SG_ DM42_16OC : 520|7@1+ (1,0) [0|0] "" Vector__XXX
 SG_ DM42_16FMI : 512|5@1+ (1,0) [0|0] "" Vector__XXX
 SG_ DM42_16SPN : 496|16@1+ (1,0) [0|0] "" Vector__XXX
 SG_ DM42_17OC : 552|7@1+ (1,0) [0|0] "" Vector__XXX
 SG_ DM42_17FMI : 544|5@1+ (1,0) [0|0] "" Vector__XXX
 SG_ DM42_17SPN : 528|16@1+ (1,0) [0|0] "" Vector__XXX
 SG_ DM42_18OC : 584|7@1+ (1,0) [0|0] "" Vector__XXX
 SG_ DM42_18FMI : 576|5@1+ (1,0) [0|0] "" Vector__XXX
 SG_ DM42_18SPN : 560|16@1+ (1,0) [0|0] "" Vector__XXX
 SG_ DM42_19OC : 616|7@1+ (1,0) [0|0] "" Vector__XXX
 SG_ DM42_19FMI : 608|5@1+ (1,0) [0|0] "" Vector__XXX
 SG_ DM42_19SPN : 592|16@1+ (1,0) [0|0] "" Vector__XXX
 SG_ DM42_19SPN_High : 613|3@1+ (65536,0) [0|0] "" Vector__XXX
 SG_ DM42_18SPN_High : 581|3@1+ (65536,0) [0|0] "" Vector__XXX
 SG_ DM42_17SPN_High : 549|3@1+ (65536,0) [0|0] "" Vector__XXX
 SG_ DM42_16SPN_High : 517|3@1+ (65536,0) [0|0] "" Vector__XXX
 SG_ DM42_15SPN_High : 485|3@1+ (65536,0) [0|0] "" Vector__XXX
 SG_ DM42_14SPN_High : 453|3@1+ (65536,0) [0|0] "" Vector__XXX
 SG_ DM42_13SPN_High : 421|3@1+ (65536,0) [0|0] "" Vector__XXX
 SG_ DM42_12SPN_High : 389|3@1+ (65536,0) [0|0] "" Vector__XXX
 SG_ DM42_11SPN_High : 357|3@1+ (65536,0) [0|0] "" Vector__XXX
 SG_ DM42_10SPN_High : 325|3@1+ (65536,0) [0|0] "" Vector__XXX
 SG_ DM42_09SPN_High : 293|3@1+ (65536,0) [0|0] "" Vector__XXX
 SG_ DM42_08SPN_High : 261|3@1+ (65536,0) [0|0] "" Vector__XXX
 SG_ DM42_07SPN_High : 229|3@1+ (65536,0) [0|0] "" Vector__XXX
 SG_ DM42_06SPN_High : 197|3@1+ (65536,0) [0|0] "" Vector__XXX
 SG_ DM42_05SPN_High : 165|3@1+ (65536,0) [0|0] "" Vector__XXX
 SG_ DM42_04SPN_High : 133|3@1+ (65536,0) [0|0] "" Vector__XXX
 SG_ DM42_03SPN_High : 101|3@1+ (65536,0) [0|0] "" Vector__XXX
 SG_ DM42_02SPN_High : 69|3@1+ (65536,0) [0|0] "" Vector__XXX
 SG_ DM42_01SPN_High : 37|3@1+ (65536,0) [0|0] "" Vector__XXX
 SG_ DM42_01CM : 47|1@1+ (1,0) [0|0] "" Vector__XXX
 SG_ DM42_02CM : 79|1@1+ (1,0) [0|0] "" Vector__XXX
 SG_ DM42_03CM : 111|1@1+ (1,0) [0|0] "" Vector__XXX
 SG_ DM42_04CM : 143|1@1+ (1,0) [0|0] "" Vector__XXX
 SG_ DM42_05CM : 175|1@1+ (1,0) [0|0] "" Vector__XXX
 SG_ DM42_06CM : 207|1@1+ (1,0) [0|0] "" Vector__XXX
 SG_ DM42_07CM : 239|1@1+ (1,0) [0|0] "" Vector__XXX
 SG_ DM42_08CM : 271|1@1+ (1,0) [0|0] "" Vector__XXX
 SG_ DM42_09CM : 303|1@1+ (1,0) [0|0] "" Vector__XXX
 SG_ DM42_10CM : 335|1@1+ (1,0) [0|0] "" Vector__XXX
 SG_ DM42_11CM : 367|1@1+ (1,0) [0|0] "" Vector__XXX
 SG_ DM42_12CM : 399|1@1+ (1,0) [0|0] "" Vector__XXX
 SG_ DM42_13CM : 431|1@1+ (1,0) [0|0] "" Vector__XXX
 SG_ DM42_14CM : 463|1@1+ (1,0) [0|0] "" Vector__XXX
 SG_ DM42_15CM : 495|1@1+ (1,0) [0|0] "" Vector__XXX
 SG_ DM42_16CM : 527|1@1+ (1,0) [0|0] "" Vector__XXX
 SG_ DM42_17CM : 559|1@1+ (1,0) [0|0] "" Vector__XXX
 SG_ DM42_18CM : 591|1@1+ (1,0) [0|0] "" Vector__XXX
 SG_ DM42_19CM : 623|1@1+ (1,0) [0|0] "" Vector__XXX

BO_ 2566742014 DM41: 78 Vector__XXX
 SG_ FlashRedStopLamp : 12|2@1+ (1,0) [0|3] "" Vector__XXX
 SG_ FlashProtectLamp : 8|2@1+ (1,0) [0|3] "" Vector__XXX
 SG_ FlashMalfuncIndicatorLamp : 14|2@1+ (1,0) [0|3] "" Vector__XXX
 SG_ FlashAmberWarningLamp : 10|2@1+ (1,0) [0|3] "" Vector__XXX
 SG_ MalfunctionIndicatorLampStatus : 6|2@1+ (1,0) [0|3] "" Vector__XXX
 SG_ AmberWarningLampStatus : 2|2@1+ (1,0) [0|3] "" Vector__XXX
 SG_ RedStopLampStatus : 4|2@1+ (1,0) [0|3] "" Vector__XXX
 SG_ ProtectLampStatus : 0|2@1+ (1,0) [0|3] "" Vector__XXX
 SG_ DM41_01OC : 40|7@1+ (1,0) [0|0] "" Vector__XXX
 SG_ DM41_01FMI : 32|5@1+ (1,0) [0|0] "" Vector__XXX
 SG_ DM41_01SPN : 16|16@1+ (1,0) [0|0] "" Vector__XXX
 SG_ DM41_02OC : 72|7@1+ (1,0) [0|0] "" Vector__XXX
 SG_ DM41_02FMI : 64|5@1+ (1,0) [0|0] "" Vector__XXX
 SG_ DM41_02SPN : 48|16@1+ (1,0) [0|0] "" Vector__XXX
 SG_ DM41_03OC : 104|7@1+ (1,0) [0|0] "" Vector__XXX
 SG_ DM41_03FMI : 96|5@1+ (1,0) [0|0] "" Vector__XXX
 SG_ DM41_03SPN : 80|16@1+ (1,0) [0|0] "" Vector__XXX
 SG_ DM41_04OC : 136|7@1+ (1,0) [0|0] "" Vector__XXX
 SG_ DM41_04FMI : 128|5@1+ (1,0) [0|0] "" Vector__XXX
 SG_ DM41_04SPN : 112|16@1+ (1,0) [0|0] "" Vector__XXX
 SG_ DM41_05OC : 168|7@1+ (1,0) [0|0] "" Vector__XXX
 SG_ DM41_05FMI : 160|5@1+ (1,0) [0|0] "" Vector__XXX
 SG_ DM41_05SPN : 144|16@1+ (1,0) [0|0] "" Vector__XXX
 SG_ DM41_06OC : 200|7@1+ (1,0) [0|0] "" Vector__XXX
 SG_ DM41_06FMI : 192|5@1+ (1,0) [0|0] "" Vector__XXX
 SG_ DM41_06SPN : 176|16@1+ (1,0) [0|0] "" Vector__XXX
 SG_ DM41_07OC : 232|7@1+ (1,0) [0|0] "" Vector__XXX
 SG_ DM41_07FMI : 224|5@1+ (1,0) [0|0] "" Vector__XXX
 SG_ DM41_07SPN : 208|16@1+ (1,0) [0|0] "" Vector__XXX
 SG_ DM41_08OC : 264|7@1+ (1,0) [0|0] "" Vector__XXX
 SG_ DM41_08FMI : 256|5@1+ (1,0) [0|0] "" Vector__XXX
 SG_ DM41_08SPN : 240|16@1+ (1,0) [0|0] "" Vector__XXX
 SG_ DM41_09OC : 296|7@1+ (1,0) [0|0] "" Vector__XXX
 SG_ DM41_09FMI : 288|5@1+ (1,0) [0|0] "" Vector__XXX
 SG_ DM41_09SPN : 272|16@1+ (1,0) [0|0] "" Vector__XXX
 SG_ DM41_10OC : 328|7@1+ (1,0) [0|0] "" Vector__XXX
 SG_ DM41_10FMI : 320|5@1+ (1,0) [0|0] "" Vector__XXX
 SG_ DM41_10SPN : 304|16@1+ (1,0) [0|0] "" Vector__XXX
 SG_ DM41_11OC : 360|7@1+ (1,0) [0|0] "" Vector__XXX
 SG_ DM41_11FMI : 352|5@1+ (1,0) [0|0] "" Vector__XXX
 SG_ DM41_11SPN : 336|16@1+ (1,0) [0|0] "" Vector__XXX
 SG_ DM41_12OC : 392|7@1+ (1,0) [0|0] "" Vector__XXX
 SG_ DM41_12FMI : 384|5@1+ (1,0) [0|0] "" Vector__XXX
 SG_ DM41_12SPN : 368|16@1+ (1,0) [0|0] "" Vector__XXX
 SG_ DM41_13OC : 424|7@1+ (1,0) [0|0] "" Vector__XXX
 SG_ DM41_13FMI : 416|5@1+ (1,0) [0|0] "" Vector__XXX
 SG_ DM41_13SPN : 400|16@1+ (1,0) [0|0] "" Vector__XXX
 SG_ DM41_14OC : 456|7@1+ (1,0) [0|0] "" Vector__XXX
 SG_ DM41_14FMI : 448|5@1+ (1,0) [0|0] "" Vector__XXX
 SG_ DM41_14SPN : 432|16@1+ (1,0) [0|0] "" Vector__XXX
 SG_ DM41_15OC : 488|7@1+ (1,0) [0|0] "" Vector__XXX
 SG_ DM41_15FMI : 480|5@1+ (1,0) [0|0] "" Vector__XXX
 SG_ DM41_15SPN : 464|16@1+ (1,0) [0|0] "" Vector__XXX
 SG_ DM41_16OC : 520|7@1+ (1,0) [0|0] "" Vector__XXX
 SG_ DM41_16FMI : 512|5@1+ (1,0) [0|0] "" Vector__XXX
 SG_ DM41_16SPN : 496|16@1+ (1,0) [0|0] "" Vector__XXX
 SG_ DM41_17OC : 552|7@1+ (1,0) [0|0] "" Vector__XXX
 SG_ DM41_17FMI : 544|5@1+ (1,0) [0|0] "" Vector__XXX
 SG_ DM41_17SPN : 528|16@1+ (1,0) [0|0] "" Vector__XXX
 SG_ DM41_18OC : 584|7@1+ (1,0) [0|0] "" Vector__XXX
 SG_ DM41_18FMI : 576|5@1+ (1,0) [0|0] "" Vector__XXX
 SG_ DM41_18SPN : 560|16@1+ (1,0) [0|0] "" Vector__XXX
 SG_ DM41_19OC : 616|7@1+ (1,0) [0|0] "" Vector__XXX
 SG_ DM41_19FMI : 608|5@1+ (1,0) [0|0] "" Vector__XXX
 SG_ DM41_19SPN : 592|16@1+ (1,0) [0|0] "" Vector__XXX
 SG_ DM41_19SPN_High : 613|3@1+ (65536,0) [0|0] "" Vector__XXX
 SG_ DM41_18SPN_High : 581|3@1+ (65536,0) [0|0] "" Vector__XXX
 SG_ DM41_17SPN_High : 549|3@1+ (65536,0) [0|0] "" Vector__XXX
 SG_ DM41_16SPN_High : 517|3@1+ (65536,0) [0|0] "" Vector__XXX
 SG_ DM41_15SPN_High : 485|3@1+ (65536,0) [0|0] "" Vector__XXX
 SG_ DM41_14SPN_High : 453|3@1+ (65536,0) [0|0] "" Vector__XXX
 SG_ DM41_13SPN_High : 421|3@1+ (65536,0) [0|0] "" Vector__XXX
 SG_ DM41_12SPN_High : 389|3@1+ (65536,0) [0|0] "" Vector__XXX
 SG_ DM41_11SPN_High : 357|3@1+ (65536,0) [0|0] "" Vector__XXX
 SG_ DM41_10SPN_High : 325|3@1+ (65536,0) [0|0] "" Vector__XXX
 SG_ DM41_09SPN_High : 293|3@1+ (65536,0) [0|0] "" Vector__XXX
 SG_ DM41_08SPN_High : 261|3@1+ (65536,0) [0|0] "" Vector__XXX
 SG_ DM41_07SPN_High : 229|3@1+ (65536,0) [0|0] "" Vector__XXX
 SG_ DM41_06SPN_High : 197|3@1+ (65536,0) [0|0] "" Vector__XXX
 SG_ DM41_05SPN_High : 165|3@1+ (65536,0) [0|0] "" Vector__XXX
 SG_ DM41_04SPN_High : 133|3@1+ (65536,0) [0|0] "" Vector__XXX
 SG_ DM41_03SPN_High : 101|3@1+ (65536,0) [0|0] "" Vector__XXX
 SG_ DM41_02SPN_High : 69|3@1+ (65536,0) [0|0] "" Vector__XXX
 SG_ DM41_01SPN_High : 37|3@1+ (65536,0) [0|0] "" Vector__XXX
 SG_ DM41_01CM : 47|1@1+ (1,0) [0|0] "" Vector__XXX
 SG_ DM41_02CM : 79|1@1+ (1,0) [0|0] "" Vector__XXX
 SG_ DM41_03CM : 111|1@1+ (1,0) [0|0] "" Vector__XXX
 SG_ DM41_04CM : 143|1@1+ (1,0) [0|0] "" Vector__XXX
 SG_ DM41_05CM : 175|1@1+ (1,0) [0|0] "" Vector__XXX
 SG_ DM41_06CM : 207|1@1+ (1,0) [0|0] "" Vector__XXX
 SG_ DM41_07CM : 239|1@1+ (1,0) [0|0] "" Vector__XXX
 SG_ DM41_08CM : 271|1@1+ (1,0) [0|0] "" Vector__XXX
 SG_ DM41_09CM : 303|1@1+ (1,0) [0|0] "" Vector__XXX
 SG_ DM41_10CM : 335|1@1+ (1,0) [0|0] "" Vector__XXX
 SG_ DM41_11CM : 367|1@1+ (1,0) [0|0] "" Vector__XXX
 SG_ DM41_12CM : 399|1@1+ (1,0) [0|0] "" Vector__XXX
 SG_ DM41_13CM : 431|1@1+ (1,0) [0|0] "" Vector__XXX
 SG_ DM41_14CM : 463|1@1+ (1,0) [0|0] "" Vector__XXX
 SG_ DM41_15CM : 495|1@1+ (1,0) [0|0] "" Vector__XXX
 SG_ DM41_16CM : 527|1@1+ (1,0) [0|0] "" Vector__XXX
 SG_ DM41_17CM : 559|1@1+ (1,0) [0|0] "" Vector__XXX
 SG_ DM41_18CM : 591|1@1+ (1,0) [0|0] "" Vector__XXX
 SG_ DM41_19CM : 623|1@1+ (1,0) [0|0] "" Vector__XXX

BO_ 2560622334 DM35: 78 Vector__XXX
 SG_ FlashRedStopLamp : 12|2@1+ (1,0) [0|3] "" Vector__XXX
 SG_ FlashProtectLamp : 8|2@1+ (1,0) [0|3] "" Vector__XXX
 SG_ FlashMalfuncIndicatorLamp : 14|2@1+ (1,0) [0|3] "" Vector__XXX
 SG_ FlashAmberWarningLamp : 10|2@1+ (1,0) [0|3] "" Vector__XXX
 SG_ MalfunctionIndicatorLampStatus : 6|2@1+ (1,0) [0|3] "" Vector__XXX
 SG_ AmberWarningLampStatus : 2|2@1+ (1,0) [0|3] "" Vector__XXX
 SG_ RedStopLampStatus : 4|2@1+ (1,0) [0|3] "" Vector__XXX
 SG_ ProtectLampStatus : 0|2@1+ (1,0) [0|3] "" Vector__XXX
 SG_ DM35_01OC : 40|7@1+ (1,0) [0|0] "" Vector__XXX
 SG_ DM35_01FMI : 32|5@1+ (1,0) [0|0] "" Vector__XXX
 SG_ DM35_01SPN : 16|16@1+ (1,0) [0|0] "" Vector__XXX
 SG_ DM35_02OC : 72|7@1+ (1,0) [0|0] "" Vector__XXX
 SG_ DM35_02FMI : 64|5@1+ (1,0) [0|0] "" Vector__XXX
 SG_ DM35_02SPN : 48|16@1+ (1,0) [0|0] "" Vector__XXX
 SG_ DM35_03OC : 104|7@1+ (1,0) [0|0] "" Vector__XXX
 SG_ DM35_03FMI : 96|5@1+ (1,0) [0|0] "" Vector__XXX
 SG_ DM35_03SPN : 80|16@1+ (1,0) [0|0] "" Vector__XXX
 SG_ DM35_04OC : 136|7@1+ (1,0) [0|0] "" Vector__XXX
 SG_ DM35_04FMI : 128|5@1+ (1,0) [0|0] "" Vector__XXX
 SG_ DM35_04SPN : 112|16@1+ (1,0) [0|0] "" Vector__XXX
 SG_ DM35_05OC : 168|7@1+ (1,0) [0|0] "" Vector__XXX
 SG_ DM35_05FMI : 160|5@1+ (1,0) [0|0] "" Vector__XXX
 SG_ DM35_05SPN : 144|16@1+ (1,0) [0|0] "" Vector__XXX
 SG_ DM35_06OC : 200|7@1+ (1,0) [0|0] "" Vector__XXX
 SG_ DM35_06FMI : 192|5@1+ (1,0) [0|0] "" Vector__XXX
 SG_ DM35_06SPN : 176|16@1+ (1,0) [0|0] "" Vector__XXX
 SG_ DM35_07OC : 232|7@1+ (1,0) [0|0] "" Vector__XXX
 SG_ DM35_07FMI : 224|5@1+ (1,0) [0|0] "" Vector__XXX
 SG_ DM35_07SPN : 208|16@1+ (1,0) [0|0] "" Vector__XXX
 SG_ DM35_08OC : 264|7@1+ (1,0) [0|0] "" Vector__XXX
 SG_ DM35_08FMI : 256|5@1+ (1,0) [0|0] "" Vector__XXX
 SG_ DM35_08SPN : 240|16@1+ (1,0) [0|0] "" Vector__XXX
 SG_ DM35_09OC : 296|7@1+ (1,0) [0|0] "" Vector__XXX
 SG_ DM35_09FMI : 288|5@1+ (1,0) [0|0] "" Vector__XXX
 SG_ DM35_09SPN : 272|16@1+ (1,0) [0|0] "" Vector__XXX
 SG_ DM35_10OC : 328|7@1+ (1,0) [0|0] "" Vector__XXX
 SG_ DM35_10FMI : 320|5@1+ (1,0) [0|0] "" Vector__XXX
 SG_ DM35_10SPN : 304|16@1+ (1,0) [0|0] "" Vector__XXX
 SG_ DM35_11OC : 360|7@1+ (1,0) [0|0] "" Vector__XXX
 SG_ DM35_11FMI : 352|5@1+ (1,0) [0|0] "" Vector__XXX
 SG_ DM35_11SPN : 336|16@1+ (1,0) [0|0] "" Vector__XXX
 SG_ DM35_12OC : 392|7@1+ (1,0) [0|0] "" Vector__XXX
 SG_ DM35_12FMI : 384|5@1+ (1,0) [0|0] "" Vector__XXX
 SG_ DM35_12SPN : 368|16@1+ (1,0) [0|0] "" Vector__XXX
 SG_ DM35_13OC : 424|7@1+ (1,0) [0|0] "" Vector__XXX
 SG_ DM35_13FMI : 416|5@1+ (1,0) [0|0] "" Vector__XXX
 SG_ DM35_13SPN : 400|16@1+ (1,0) [0|0] "" Vector__XXX
 SG_ DM35_14OC : 456|7@1+ (1,0) [0|0] "" Vector__XXX
 SG_ DM35_14FMI : 448|5@1+ (1,0) [0|0] "" Vector__XXX
 SG_ DM35_14SPN : 432|16@1+ (1,0) [0|0] "" Vector__XXX
 SG_ DM35_15OC : 488|7@1+ (1,0) [0|0] "" Vector__XXX
 SG_ DM35_15FMI : 480|5@1+ (1,0) [0|0] "" Vector__XXX
 SG_ DM35_15SPN : 464|16@1+ (1,0) [0|0] "" Vector__XXX
 SG_ DM35_16OC : 520|7@1+ (1,0) [0|0] "" Vector__XXX
 SG_ DM35_16FMI : 512|5@1+ (1,0) [0|0] "" Vector__XXX
 SG_ DM35_16SPN : 496|16@1+ (1,0) [0|0] "" Vector__XXX
 SG_ DM35_17OC : 552|7@1+ (1,0) [0|0] "" Vector__XXX
 SG_ DM35_17FMI : 544|5@1+ (1,0) [0|0] "" Vector__XXX
 SG_ DM35_17SPN : 528|16@1+ (1,0) [0|0] "" Vector__XXX
 SG_ DM35_18OC : 584|7@1+ (1,0) [0|0] "" Vector__XXX
 SG_ DM35_18FMI : 576|5@1+ (1,0) [0|0] "" Vector__XXX
 SG_ DM35_18SPN : 560|16@1+ (1,0) [0|0] "" Vector__XXX
 SG_ DM35_19OC : 616|7@1+ (1,0) [0|0] "" Vector__XXX
 SG_ DM35_19FMI : 608|5@1+ (1,0) [0|0] "" Vector__XXX
 SG_ DM35_19SPN : 592|16@1+ (1,0) [0|0] "" Vector__XXX
 SG_ DM35_19SPN_High : 613|3@1+ (65536,0) [0|0] "" Vector__XXX
 SG_ DM35_18SPN_High : 581|3@1+ (65536,0) [0|0] "" Vector__XXX
 SG_ DM35_17SPN_High : 549|3@1+ (65536,0) [0|0] "" Vector__XXX
 SG_ DM35_16SPN_High : 517|3@1+ (65536,0) [0|0] "" Vector__XXX
 SG_ DM35_15SPN_High : 485|3@1+ (65536,0) [0|0] "" Vector__XXX
 SG_ DM35_14SPN_High : 453|3@1+ (65536,0) [0|0] "" Vector__XXX
 SG_ DM35_13SPN_High : 421|3@1+ (65536,0) [0|0] "" Vector__XXX
 SG_ DM35_12SPN_High : 389|3@1+ (65536,0) [0|0] "" Vector__XXX
 SG_ DM35_11SPN_High : 357|3@1+ (65536,0) [0|0] "" Vector__XXX
 SG_ DM35_10SPN_High : 325|3@1+ (65536,0) [0|0] "" Vector__XXX
 SG_ DM35_09SPN_High : 293|3@1+ (65536,0) [0|0] "" Vector__XXX
 SG_ DM35_08SPN_High : 261|3@1+ (65536,0) [0|0] "" Vector__XXX
 SG_ DM35_07SPN_High : 229|3@1+ (65536,0) [0|0] "" Vector__XXX
 SG_ DM35_06SPN_High : 197|3@1+ (65536,0) [0|0] "" Vector__XXX
 SG_ DM35_05SPN_High : 165|3@1+ (65536,0) [0|0] "" Vector__XXX
 SG_ DM35_04SPN_High : 133|3@1+ (65536,0) [0|0] "" Vector__XXX
 SG_ DM35_03SPN_High : 101|3@1+ (65536,0) [0|0] "" Vector__XXX
 SG_ DM35_02SPN_High : 69|3@1+ (65536,0) [0|0] "" Vector__XXX
 SG_ DM35_01SPN_High : 37|3@1+ (65536,0) [0|0] "" Vector__XXX
 SG_ DM35_01CM : 47|1@1+ (1,0) [0|0] "" Vector__XXX
 SG_ DM35_02CM : 79|1@1+ (1,0) [0|0] "" Vector__XXX
 SG_ DM35_03CM : 111|1@1+ (1,0) [0|0] "" Vector__XXX
 SG_ DM35_04CM : 143|1@1+ (1,0) [0|0] "" Vector__XXX
 SG_ DM35_05CM : 175|1@1+ (1,0) [0|0] "" Vector__XXX
 SG_ DM35_06CM : 207|1@1+ (1,0) [0|0] "" Vector__XXX
 SG_ DM35_07CM : 239|1@1+ (1,0) [0|0] "" Vector__XXX
 SG_ DM35_08CM : 271|1@1+ (1,0) [0|0] "" Vector__XXX
 SG_ DM35_09CM : 303|1@1+ (1,0) [0|0] "" Vector__XXX
 SG_ DM35_10CM : 335|1@1+ (1,0) [0|0] "" Vector__XXX
 SG_ DM35_11CM : 367|1@1+ (1,0) [0|0] "" Vector__XXX
 SG_ DM35_12CM : 399|1@1+ (1,0) [0|0] "" Vector__XXX
 SG_ DM35_13CM : 431|1@1+ (1,0) [0|0] "" Vector__XXX
 SG_ DM35_14CM : 463|1@1+ (1,0) [0|0] "" Vector__XXX
 SG_ DM35_15CM : 495|1@1+ (1,0) [0|0] "" Vector__XXX
 SG_ DM35_16CM : 527|1@1+ (1,0) [0|0] "" Vector__XXX
 SG_ DM35_17CM : 559|1@1+ (1,0) [0|0] "" Vector__XXX
 SG_ DM35_18CM : 591|1@1+ (1,0) [0|0] "" Vector__XXX
 SG_ DM35_19CM : 623|1@1+ (1,0) [0|0] "" Vector__XXX

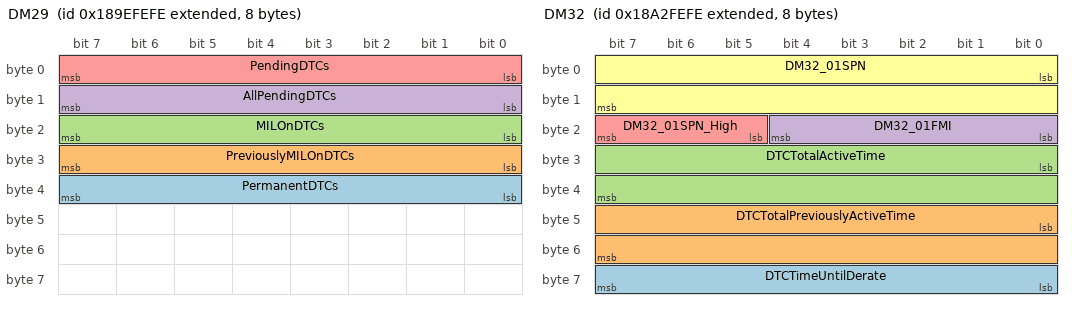
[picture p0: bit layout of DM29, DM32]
BO_ 2560556798 DM29: 8 Vector__XXX
 SG_ PermanentDTCs : 32|8@1+ (1,0) [0|255] "" Vector__XXX
 SG_ PreviouslyMILOnDTCs : 24|8@1+ (1,0) [0|255] "" Vector__XXX
 SG_ MILOnDTCs : 16|8@1+ (1,0) [0|255] "" Vector__XXX
 SG_ AllPendingDTCs : 8|8@1+ (1,0) [0|255] "" Vector__XXX
 SG_ PendingDTCs : 0|8@1+ (1,0) [0|255] "" Vector__XXX

BO_ 2566750462 DM28: 78 Vector__XXX
 SG_ FlashRedStopLamp : 12|2@1+ (1,0) [0|3] "" Vector__XXX
 SG_ FlashProtectLamp : 8|2@1+ (1,0) [0|3] "" Vector__XXX
 SG_ FlashMalfuncIndicatorLamp : 14|2@1+ (1,0) [0|3] "" Vector__XXX
 SG_ FlashAmberWarningLamp : 10|2@1+ (1,0) [0|3] "" Vector__XXX
 SG_ MalfunctionIndicatorLampStatus : 6|2@1+ (1,0) [0|3] "" Vector__XXX
 SG_ AmberWarningLampStatus : 2|2@1+ (1,0) [0|3] "" Vector__XXX
 SG_ RedStopLampStatus : 4|2@1+ (1,0) [0|3] "" Vector__XXX
 SG_ ProtectLampStatus : 0|2@1+ (1,0) [0|3] "" Vector__XXX
 SG_ DM28_01OC : 40|7@1+ (1,0) [0|0] "" Vector__XXX
 SG_ DM28_01FMI : 32|5@1+ (1,0) [0|0] "" Vector__XXX
 SG_ DM28_01SPN : 16|16@1+ (1,0) [0|0] "" Vector__XXX
 SG_ DM28_02OC : 72|7@1+ (1,0) [0|0] "" Vector__XXX
 SG_ DM28_02FMI : 64|5@1+ (1,0) [0|0] "" Vector__XXX
 SG_ DM28_02SPN : 48|16@1+ (1,0) [0|0] "" Vector__XXX
 SG_ DM28_03OC : 104|7@1+ (1,0) [0|0] "" Vector__XXX
 SG_ DM28_03FMI : 96|5@1+ (1,0) [0|0] "" Vector__XXX
 SG_ DM28_03SPN : 80|16@1+ (1,0) [0|0] "" Vector__XXX
 SG_ DM28_04OC : 136|7@1+ (1,0) [0|0] "" Vector__XXX
 SG_ DM28_04FMI : 128|5@1+ (1,0) [0|0] "" Vector__XXX
 SG_ DM28_04SPN : 112|16@1+ (1,0) [0|0] "" Vector__XXX
 SG_ DM28_05OC : 168|7@1+ (1,0) [0|0] "" Vector__XXX
 SG_ DM28_05FMI : 160|5@1+ (1,0) [0|0] "" Vector__XXX
 SG_ DM28_05SPN : 144|16@1+ (1,0) [0|0] "" Vector__XXX
 SG_ DM28_06OC : 200|7@1+ (1,0) [0|0] "" Vector__XXX
 SG_ DM28_06FMI : 192|5@1+ (1,0) [0|0] "" Vector__XXX
 SG_ DM28_06SPN : 176|16@1+ (1,0) [0|0] "" Vector__XXX
 SG_ DM28_07OC : 232|7@1+ (1,0) [0|0] "" Vector__XXX
 SG_ DM28_07FMI : 224|5@1+ (1,0) [0|0] "" Vector__XXX
 SG_ DM28_07SPN : 208|16@1+ (1,0) [0|0] "" Vector__XXX
 SG_ DM28_08OC : 264|7@1+ (1,0) [0|0] "" Vector__XXX
 SG_ DM28_08FMI : 256|5@1+ (1,0) [0|0] "" Vector__XXX
 SG_ DM28_08SPN : 240|16@1+ (1,0) [0|0] "" Vector__XXX
 SG_ DM28_09OC : 296|7@1+ (1,0) [0|0] "" Vector__XXX
 SG_ DM28_09FMI : 288|5@1+ (1,0) [0|0] "" Vector__XXX
 SG_ DM28_09SPN : 272|16@1+ (1,0) [0|0] "" Vector__XXX
 SG_ DM28_10OC : 328|7@1+ (1,0) [0|0] "" Vector__XXX
 SG_ DM28_10FMI : 320|5@1+ (1,0) [0|0] "" Vector__XXX
 SG_ DM28_10SPN : 304|16@1+ (1,0) [0|0] "" Vector__XXX
 SG_ DM28_11OC : 360|7@1+ (1,0) [0|0] "" Vector__XXX
 SG_ DM28_11FMI : 352|5@1+ (1,0) [0|0] "" Vector__XXX
 SG_ DM28_11SPN : 336|16@1+ (1,0) [0|0] "" Vector__XXX
 SG_ DM28_12OC : 392|7@1+ (1,0) [0|0] "" Vector__XXX
 SG_ DM28_12FMI : 384|5@1+ (1,0) [0|0] "" Vector__XXX
 SG_ DM28_12SPN : 368|16@1+ (1,0) [0|0] "" Vector__XXX
 SG_ DM28_13OC : 424|7@1+ (1,0) [0|0] "" Vector__XXX
 SG_ DM28_13FMI : 416|5@1+ (1,0) [0|0] "" Vector__XXX
 SG_ DM28_13SPN : 400|16@1+ (1,0) [0|0] "" Vector__XXX
 SG_ DM28_14OC : 456|7@1+ (1,0) [0|0] "" Vector__XXX
 SG_ DM28_14FMI : 448|5@1+ (1,0) [0|0] "" Vector__XXX
 SG_ DM28_14SPN : 432|16@1+ (1,0) [0|0] "" Vector__XXX
 SG_ DM28_15OC : 488|7@1+ (1,0) [0|0] "" Vector__XXX
 SG_ DM28_15FMI : 480|5@1+ (1,0) [0|0] "" Vector__XXX
 SG_ DM28_15SPN : 464|16@1+ (1,0) [0|0] "" Vector__XXX
 SG_ DM28_16OC : 520|7@1+ (1,0) [0|0] "" Vector__XXX
 SG_ DM28_16FMI : 512|5@1+ (1,0) [0|0] "" Vector__XXX
 SG_ DM28_16SPN : 496|16@1+ (1,0) [0|0] "" Vector__XXX
 SG_ DM28_17OC : 552|7@1+ (1,0) [0|0] "" Vector__XXX
 SG_ DM28_17FMI : 544|5@1+ (1,0) [0|0] "" Vector__XXX
 SG_ DM28_17SPN : 528|16@1+ (1,0) [0|0] "" Vector__XXX
 SG_ DM28_18OC : 584|7@1+ (1,0) [0|0] "" Vector__XXX
 SG_ DM28_18FMI : 576|5@1+ (1,0) [0|0] "" Vector__XXX
 SG_ DM28_18SPN : 560|16@1+ (1,0) [0|0] "" Vector__XXX
 SG_ DM28_19OC : 616|7@1+ (1,0) [0|0] "" Vector__XXX
 SG_ DM28_19FMI : 608|5@1+ (1,0) [0|0] "" Vector__XXX
 SG_ DM28_19SPN : 592|16@1+ (1,0) [0|0] "" Vector__XXX
 SG_ DM28_19SPN_High : 613|3@1+ (65536,0) [0|0] "" Vector__XXX
 SG_ DM28_18SPN_High : 581|3@1+ (65536,0) [0|0] "" Vector__XXX
 SG_ DM28_17SPN_High : 549|3@1+ (65536,0) [0|0] "" Vector__XXX
 SG_ DM28_16SPN_High : 517|3@1+ (65536,0) [0|0] "" Vector__XXX
 SG_ DM28_15SPN_High : 485|3@1+ (65536,0) [0|0] "" Vector__XXX
 SG_ DM28_14SPN_High : 453|3@1+ (65536,0) [0|0] "" Vector__XXX
 SG_ DM28_13SPN_High : 421|3@1+ (65536,0) [0|0] "" Vector__XXX
 SG_ DM28_12SPN_High : 389|3@1+ (65536,0) [0|0] "" Vector__XXX
 SG_ DM28_11SPN_High : 357|3@1+ (65536,0) [0|0] "" Vector__XXX
 SG_ DM28_10SPN_High : 325|3@1+ (65536,0) [0|0] "" Vector__XXX
 SG_ DM28_09SPN_High : 293|3@1+ (65536,0) [0|0] "" Vector__XXX
 SG_ DM28_08SPN_High : 261|3@1+ (65536,0) [0|0] "" Vector__XXX
 SG_ DM28_07SPN_High : 229|3@1+ (65536,0) [0|0] "" Vector__XXX
 SG_ DM28_06SPN_High : 197|3@1+ (65536,0) [0|0] "" Vector__XXX
 SG_ DM28_05SPN_High : 165|3@1+ (65536,0) [0|0] "" Vector__XXX
 SG_ DM28_04SPN_High : 133|3@1+ (65536,0) [0|0] "" Vector__XXX
 SG_ DM28_03SPN_High : 101|3@1+ (65536,0) [0|0] "" Vector__XXX
 SG_ DM28_02SPN_High : 69|3@1+ (65536,0) [0|0] "" Vector__XXX
 SG_ DM28_01SPN_High : 37|3@1+ (65536,0) [0|0] "" Vector__XXX
 SG_ DM28_01CM : 47|1@1+ (1,0) [0|0] "" Vector__XXX
 SG_ DM28_02CM : 79|1@1+ (1,0) [0|0] "" Vector__XXX
 SG_ DM28_03CM : 111|1@1+ (1,0) [0|0] "" Vector__XXX
 SG_ DM28_04CM : 143|1@1+ (1,0) [0|0] "" Vector__XXX
 SG_ DM28_05CM : 175|1@1+ (1,0) [0|0] "" Vector__XXX
 SG_ DM28_06CM : 207|1@1+ (1,0) [0|0] "" Vector__XXX
 SG_ DM28_07CM : 239|1@1+ (1,0) [0|0] "" Vector__XXX
 SG_ DM28_08CM : 271|1@1+ (1,0) [0|0] "" Vector__XXX
 SG_ DM28_09CM : 303|1@1+ (1,0) [0|0] "" Vector__XXX
 SG_ DM28_10CM : 335|1@1+ (1,0) [0|0] "" Vector__XXX
 SG_ DM28_11CM : 367|1@1+ (1,0) [0|0] "" Vector__XXX
 SG_ DM28_12CM : 399|1@1+ (1,0) [0|0] "" Vector__XXX
 SG_ DM28_13CM : 431|1@1+ (1,0) [0|0] "" Vector__XXX
 SG_ DM28_14CM : 463|1@1+ (1,0) [0|0] "" Vector__XXX
 SG_ DM28_15CM : 495|1@1+ (1,0) [0|0] "" Vector__XXX
 SG_ DM28_16CM : 527|1@1+ (1,0) [0|0] "" Vector__XXX
 SG_ DM28_17CM : 559|1@1+ (1,0) [0|0] "" Vector__XXX
 SG_ DM28_18CM : 591|1@1+ (1,0) [0|0] "" Vector__XXX
 SG_ DM28_19CM : 623|1@1+ (1,0) [0|0] "" Vector__XXX

BO_ 2566750974 DM27: 78 Vector__XXX
 SG_ FlashRedStopLamp : 12|2@1+ (1,0) [0|3] "" Vector__XXX
 SG_ FlashProtectLamp : 8|2@1+ (1,0) [0|3] "" Vector__XXX
 SG_ FlashMalfuncIndicatorLamp : 14|2@1+ (1,0) [0|3] "" Vector__XXX
 SG_ FlashAmberWarningLamp : 10|2@1+ (1,0) [0|3] "" Vector__XXX
 SG_ MalfunctionIndicatorLampStatus : 6|2@1+ (1,0) [0|3] "" Vector__XXX
 SG_ AmberWarningLampStatus : 2|2@1+ (1,0) [0|3] "" Vector__XXX
 SG_ RedStopLampStatus : 4|2@1+ (1,0) [0|3] "" Vector__XXX
 SG_ ProtectLampStatus : 0|2@1+ (1,0) [0|3] "" Vector__XXX
 SG_ DM27_01OC : 40|7@1+ (1,0) [0|0] "" Vector__XXX
 SG_ DM27_01FMI : 32|5@1+ (1,0) [0|0] "" Vector__XXX
 SG_ DM27_01SPN : 16|16@1+ (1,0) [0|0] "" Vector__XXX
 SG_ DM27_02OC : 72|7@1+ (1,0) [0|0] "" Vector__XXX
 SG_ DM27_02FMI : 64|5@1+ (1,0) [0|0] "" Vector__XXX
 SG_ DM27_02SPN : 48|16@1+ (1,0) [0|0] "" Vector__XXX
 SG_ DM27_03OC : 104|7@1+ (1,0) [0|0] "" Vector__XXX
 SG_ DM27_03FMI : 96|5@1+ (1,0) [0|0] "" Vector__XXX
 SG_ DM27_03SPN : 80|16@1+ (1,0) [0|0] "" Vector__XXX
 SG_ DM27_04OC : 136|7@1+ (1,0) [0|0] "" Vector__XXX
 SG_ DM27_04FMI : 128|5@1+ (1,0) [0|0] "" Vector__XXX
 SG_ DM27_04SPN : 112|16@1+ (1,0) [0|0] "" Vector__XXX
 SG_ DM27_05OC : 168|7@1+ (1,0) [0|0] "" Vector__XXX
 SG_ DM27_05FMI : 160|5@1+ (1,0) [0|0] "" Vector__XXX
 SG_ DM27_05SPN : 144|16@1+ (1,0) [0|0] "" Vector__XXX
 SG_ DM27_06OC : 200|7@1+ (1,0) [0|0] "" Vector__XXX
 SG_ DM27_06FMI : 192|5@1+ (1,0) [0|0] "" Vector__XXX
 SG_ DM27_06SPN : 176|16@1+ (1,0) [0|0] "" Vector__XXX
 SG_ DM27_07OC : 232|7@1+ (1,0) [0|0] "" Vector__XXX
 SG_ DM27_07FMI : 224|5@1+ (1,0) [0|0] "" Vector__XXX
 SG_ DM27_07SPN : 208|16@1+ (1,0) [0|0] "" Vector__XXX
 SG_ DM27_08OC : 264|7@1+ (1,0) [0|0] "" Vector__XXX
 SG_ DM27_08FMI : 256|5@1+ (1,0) [0|0] "" Vector__XXX
 SG_ DM27_08SPN : 240|16@1+ (1,0) [0|0] "" Vector__XXX
 SG_ DM27_09OC : 296|7@1+ (1,0) [0|0] "" Vector__XXX
 SG_ DM27_09FMI : 288|5@1+ (1,0) [0|0] "" Vector__XXX
 SG_ DM27_09SPN : 272|16@1+ (1,0) [0|0] "" Vector__XXX
 SG_ DM27_10OC : 328|7@1+ (1,0) [0|0] "" Vector__XXX
 SG_ DM27_10FMI : 320|5@1+ (1,0) [0|0] "" Vector__XXX
 SG_ DM27_10SPN : 304|16@1+ (1,0) [0|0] "" Vector__XXX
 SG_ DM27_11OC : 360|7@1+ (1,0) [0|0] "" Vector__XXX
 SG_ DM27_11FMI : 352|5@1+ (1,0) [0|0] "" Vector__XXX
 SG_ DM27_11SPN : 336|16@1+ (1,0) [0|0] "" Vector__XXX
 SG_ DM27_12OC : 392|7@1+ (1,0) [0|0] "" Vector__XXX
 SG_ DM27_12FMI : 384|5@1+ (1,0) [0|0] "" Vector__XXX
 SG_ DM27_12SPN : 368|16@1+ (1,0) [0|0] "" Vector__XXX
 SG_ DM27_13OC : 424|7@1+ (1,0) [0|0] "" Vector__XXX
 SG_ DM27_13FMI : 416|5@1+ (1,0) [0|0] "" Vector__XXX
 SG_ DM27_13SPN : 400|16@1+ (1,0) [0|0] "" Vector__XXX
 SG_ DM27_14OC : 456|7@1+ (1,0) [0|0] "" Vector__XXX
 SG_ DM27_14FMI : 448|5@1+ (1,0) [0|0] "" Vector__XXX
 SG_ DM27_14SPN : 432|16@1+ (1,0) [0|0] "" Vector__XXX
 SG_ DM27_15OC : 488|7@1+ (1,0) [0|0] "" Vector__XXX
 SG_ DM27_15FMI : 480|5@1+ (1,0) [0|0] "" Vector__XXX
 SG_ DM27_15SPN : 464|16@1+ (1,0) [0|0] "" Vector__XXX
 SG_ DM27_16OC : 520|7@1+ (1,0) [0|0] "" Vector__XXX
 SG_ DM27_16FMI : 512|5@1+ (1,0) [0|0] "" Vector__XXX
 SG_ DM27_16SPN : 496|16@1+ (1,0) [0|0] "" Vector__XXX
 SG_ DM27_17OC : 552|7@1+ (1,0) [0|0] "" Vector__XXX
 SG_ DM27_17FMI : 544|5@1+ (1,0) [0|0] "" Vector__XXX
 SG_ DM27_17SPN : 528|16@1+ (1,0) [0|0] "" Vector__XXX
 SG_ DM27_18OC : 584|7@1+ (1,0) [0|0] "" Vector__XXX
 SG_ DM27_18FMI : 576|5@1+ (1,0) [0|0] "" Vector__XXX
 SG_ DM27_18SPN : 560|16@1+ (1,0) [0|0] "" Vector__XXX
 SG_ DM27_19OC : 616|7@1+ (1,0) [0|0] "" Vector__XXX
 SG_ DM27_19FMI : 608|5@1+ (1,0) [0|0] "" Vector__XXX
 SG_ DM27_19SPN : 592|16@1+ (1,0) [0|0] "" Vector__XXX
 SG_ DM27_19SPN_High : 613|3@1+ (65536,0) [0|0] "" Vector__XXX
 SG_ DM27_18SPN_High : 581|3@1+ (65536,0) [0|0] "" Vector__XXX
 SG_ DM27_17SPN_High : 549|3@1+ (65536,0) [0|0] "" Vector__XXX
 SG_ DM27_16SPN_High : 517|3@1+ (65536,0) [0|0] "" Vector__XXX
 SG_ DM27_15SPN_High : 485|3@1+ (65536,0) [0|0] "" Vector__XXX
 SG_ DM27_14SPN_High : 453|3@1+ (65536,0) [0|0] "" Vector__XXX
 SG_ DM27_13SPN_High : 421|3@1+ (65536,0) [0|0] "" Vector__XXX
 SG_ DM27_12SPN_High : 389|3@1+ (65536,0) [0|0] "" Vector__XXX
 SG_ DM27_11SPN_High : 357|3@1+ (65536,0) [0|0] "" Vector__XXX
 SG_ DM27_10SPN_High : 325|3@1+ (65536,0) [0|0] "" Vector__XXX
 SG_ DM27_09SPN_High : 293|3@1+ (65536,0) [0|0] "" Vector__XXX
 SG_ DM27_08SPN_High : 261|3@1+ (65536,0) [0|0] "" Vector__XXX
 SG_ DM27_07SPN_High : 229|3@1+ (65536,0) [0|0] "" Vector__XXX
 SG_ DM27_06SPN_High : 197|3@1+ (65536,0) [0|0] "" Vector__XXX
 SG_ DM27_05SPN_High : 165|3@1+ (65536,0) [0|0] "" Vector__XXX
 SG_ DM27_04SPN_High : 133|3@1+ (65536,0) [0|0] "" Vector__XXX
 SG_ DM27_03SPN_High : 101|3@1+ (65536,0) [0|0] "" Vector__XXX
 SG_ DM27_02SPN_High : 69|3@1+ (65536,0) [0|0] "" Vector__XXX
 SG_ DM27_01SPN_High : 37|3@1+ (65536,0) [0|0] "" Vector__XXX
 SG_ DM27_01CM : 47|1@1+ (1,0) [0|0] "" Vector__XXX
 SG_ DM27_02CM : 79|1@1+ (1,0) [0|0] "" Vector__XXX
 SG_ DM27_03CM : 111|1@1+ (1,0) [0|0] "" Vector__XXX
 SG_ DM27_04CM : 143|1@1+ (1,0) [0|0] "" Vector__XXX
 SG_ DM27_05CM : 175|1@1+ (1,0) [0|0] "" Vector__XXX
 SG_ DM27_06CM : 207|1@1+ (1,0) [0|0] "" Vector__XXX
 SG_ DM27_07CM : 239|1@1+ (1,0) [0|0] "" Vector__XXX
 SG_ DM27_08CM : 271|1@1+ (1,0) [0|0] "" Vector__XXX
 SG_ DM27_09CM : 303|1@1+ (1,0) [0|0] "" Vector__XXX
 SG_ DM27_10CM : 335|1@1+ (1,0) [0|0] "" Vector__XXX
 SG_ DM27_11CM : 367|1@1+ (1,0) [0|0] "" Vector__XXX
 SG_ DM27_12CM : 399|1@1+ (1,0) [0|0] "" Vector__XXX
 SG_ DM27_13CM : 431|1@1+ (1,0) [0|0] "" Vector__XXX
 SG_ DM27_14CM : 463|1@1+ (1,0) [0|0] "" Vector__XXX
 SG_ DM27_15CM : 495|1@1+ (1,0) [0|0] "" Vector__XXX
 SG_ DM27_16CM : 527|1@1+ (1,0) [0|0] "" Vector__XXX
 SG_ DM27_17CM : 559|1@1+ (1,0) [0|0] "" Vector__XXX
 SG_ DM27_18CM : 591|1@1+ (1,0) [0|0] "" Vector__XXX
 SG_ DM27_19CM : 623|1@1+ (1,0) [0|0] "" Vector__XXX

BO_ 2560818942 DM32: 8 Vector__XXX
 SG_ DTCTimeUntilDerate : 56|8@1+ (0.25,0) [0|62.5] "hr" Vector__XXX
 SG_ DTCTotalPreviouslyActiveTime : 40|16@1+ (0.2,0) [0|12851] "hr" Vector__XXX
 SG_ DTCTotalActiveTime : 24|16@1+ (0.2,0) [0|12851] "hr" Vector__XXX
 SG_ DM32_01FMI : 16|5@1+ (1,0) [0|0] "" Vector__XXX
 SG_ DM32_01SPN_High : 21|3@1+ (65536,0) [0|0] "" Vector__XXX
 SG_ DM32_01SPN : 0|16@1+ (1,0) [0|65536] "" Vector__XXX

CM_ BO_ 2566739710 "DTCs - C, Pending";
CM_ SG_ 2566739710 FlashRedStopLamp "This parameter provides the capability to flash the RSL (SPN 3039).";
CM_ SG_ 2566739710 FlashProtectLamp "This parameter provides the capability to flash the engine protect lamp (SPN 3041).";
CM_ SG_ 2566739710 FlashMalfuncIndicatorLamp "This parameter provides the capability to flash the MIL (SPN 3038).";
CM_ SG_ 2566739710 FlashAmberWarningLamp "This parameter provides the capability to flash the AWL (SPN 3040). ";
CM_ SG_ 2566739710 MalfunctionIndicatorLampStatus "A lamp used to relay only emissions-related trouble code information.";
CM_ SG_ 2566739710 AmberWarningLampStatus "This lamp is used to relay trouble code information that is reporting a problem with the vehicle system but the vehicle need
not be immediately stopped.";
CM_ SG_ 2566739710 RedStopLampStatus "This lamp is uesed to relay trouble code information that is of a severe enought condition that it warrants stopping the vehicle.";
CM_ SG_ 2566739710 ProtectLampStatus "This lamp is used to relay trouble code informatio that is reporting a problem with a vehicle system that is most
probably not electronic subsystem related.";
CM_ BO_ 2566739966 "DTCs - B2, Previously Active";
CM_ SG_ 2566739966 FlashRedStopLamp "This parameter provides the capability to flash the RSL (SPN 3039).";
CM_ SG_ 2566739966 FlashProtectLamp "This parameter provides the capability to flash the engine protect lamp (SPN 3041).";
CM_ SG_ 2566739966 FlashMalfuncIndicatorLamp "This parameter provides the capability to flash the MIL (SPN 3038).";
CM_ SG_ 2566739966 FlashAmberWarningLamp "This parameter provides the capability to flash the AWL (SPN 3040). ";
CM_ SG_ 2566739966 MalfunctionIndicatorLampStatus "A lamp used to relay only emissions-related trouble code information.";
CM_ SG_ 2566739966 AmberWarningLampStatus "This lamp is used to relay trouble code information that is reporting a problem with the vehicle system but the vehicle need
not be immediately stopped.";
CM_ SG_ 2566739966 RedStopLampStatus "This lamp is uesed to relay trouble code information that is of a severe enought condition that it warrants stopping the vehicle.";
CM_ SG_ 2566739966 ProtectLampStatus "This lamp is used to relay trouble code informatio that is reporting a problem with a vehicle system that is most
probably not electronic subsystem related.";
CM_ BO_ 2566740222 "DTCs - B2, Confirmed and Active";
CM_ SG_ 2566740222 FlashRedStopLamp "This parameter provides the capability to flash the RSL (SPN 3039).";
CM_ SG_ 2566740222 FlashProtectLamp "This parameter provides the capability to flash the engine protect lamp (SPN 3041).";
CM_ SG_ 2566740222 FlashMalfuncIndicatorLamp "This parameter provides the capability to flash the MIL (SPN 3038).";
CM_ SG_ 2566740222 FlashAmberWarningLamp "This parameter provides the capability to flash the AWL (SPN 3040). ";
CM_ SG_ 2566740222 MalfunctionIndicatorLampStatus "A lamp used to relay only emissions-related trouble code information.";
CM_ SG_ 2566740222 AmberWarningLampStatus "This lamp is used to relay trouble code information that is reporting a problem with the vehicle system but the vehicle need
not be immediately stopped.";
CM_ SG_ 2566740222 RedStopLampStatus "This lamp is uesed to relay trouble code information that is of a severe enought condition that it warrants stopping the vehicle.";
CM_ SG_ 2566740222 ProtectLampStatus "This lamp is used to relay trouble code informatio that is reporting a problem with a vehicle system that is most
probably not electronic subsystem related.";
CM_ BO_ 2566740478 "DTCs - B2, Pending";
CM_ SG_ 2566740478 FlashRedStopLamp "This parameter provides the capability to flash the RSL (SPN 3039).";
CM_ SG_ 2566740478 FlashProtectLamp "This parameter provides the capability to flash the engine protect lamp (SPN 3041).";
CM_ SG_ 2566740478 FlashMalfuncIndicatorLamp "This parameter provides the capability to flash the MIL (SPN 3038).";
CM_ SG_ 2566740478 FlashAmberWarningLamp "This parameter provides the capability to flash the AWL (SPN 3040). ";
CM_ SG_ 2566740478 MalfunctionIndicatorLampStatus "A lamp used to relay only emissions-related trouble code information.";
CM_ SG_ 2566740478 AmberWarningLampStatus "This lamp is used to relay trouble code information that is reporting a problem with the vehicle system but the vehicle need
not be immediately stopped.";
CM_ SG_ 2566740478 RedStopLampStatus "This lamp is uesed to relay trouble code information that is of a severe enought condition that it warrants stopping the vehicle.";
CM_ SG_ 2566740478 ProtectLampStatus "This lamp is used to relay trouble code informatio that is reporting a problem with a vehicle system that is most
probably not electronic subsystem related.";
CM_ BO_ 2566740734 "DTCs - B1, Previously Active";
CM_ SG_ 2566740734 FlashRedStopLamp "This parameter provides the capability to flash the RSL (SPN 3039).";
CM_ SG_ 2566740734 FlashProtectLamp "This parameter provides the capability to flash the engine protect lamp (SPN 3041).";
CM_ SG_ 2566740734 FlashMalfuncIndicatorLamp "This parameter provides the capability to flash the MIL (SPN 3038).";
CM_ SG_ 2566740734 FlashAmberWarningLamp "This parameter provides the capability to flash the AWL (SPN 3040). ";
CM_ SG_ 2566740734 MalfunctionIndicatorLampStatus "A lamp used to relay only emissions-related trouble code information.";
CM_ SG_ 2566740734 AmberWarningLampStatus "This lamp is used to relay trouble code information that is reporting a problem with the vehicle system but the vehicle need
not be immediately stopped.";
CM_ SG_ 2566740734 RedStopLampStatus "This lamp is uesed to relay trouble code information that is of a severe enought condition that it warrants stopping the vehicle.";
CM_ SG_ 2566740734 ProtectLampStatus "This lamp is used to relay trouble code informatio that is reporting a problem with a vehicle system that is most
probably not electronic subsystem related.";
CM_ BO_ 2566740990 "DTCs - B1, Confirmed and Active";
CM_ SG_ 2566740990 FlashRedStopLamp "This parameter provides the capability to flash the RSL (SPN 3039).";
CM_ SG_ 2566740990 FlashProtectLamp "This parameter provides the capability to flash the engine protect lamp (SPN 3041).";
CM_ SG_ 2566740990 FlashMalfuncIndicatorLamp "This parameter provides the capability to flash the MIL (SPN 3038).";
CM_ SG_ 2566740990 FlashAmberWarningLamp "This parameter provides the capability to flash the AWL (SPN 3040). ";
CM_ SG_ 2566740990 MalfunctionIndicatorLampStatus "A lamp used to relay only emissions-related trouble code information.";
CM_ SG_ 2566740990 AmberWarningLampStatus "This lamp is used to relay trouble code information that is reporting a problem with the vehicle system but the vehicle need
not be immediately stopped.";
CM_ SG_ 2566740990 RedStopLampStatus "This lamp is uesed to relay trouble code information that is of a severe enought condition that it warrants stopping the vehicle.";
CM_ SG_ 2566740990 ProtectLampStatus "This lamp is used to relay trouble code informatio that is reporting a problem with a vehicle system that is most
probably not electronic subsystem related.";
CM_ BO_ 2566741246 "DTCs - B1, Pending";
CM_ SG_ 2566741246 FlashRedStopLamp "This parameter provides the capability to flash the RSL (SPN 3039).";
CM_ SG_ 2566741246 FlashProtectLamp "This parameter provides the capability to flash the engine protect lamp (SPN 3041).";
CM_ SG_ 2566741246 FlashMalfuncIndicatorLamp "This parameter provides the capability to flash the MIL (SPN 3038).";
CM_ SG_ 2566741246 FlashAmberWarningLamp "This parameter provides the capability to flash the AWL (SPN 3040). ";
CM_ SG_ 2566741246 MalfunctionIndicatorLampStatus "A lamp used to relay only emissions-related trouble code information.";
CM_ SG_ 2566741246 AmberWarningLampStatus "This lamp is used to relay trouble code information that is reporting a problem with the vehicle system but the vehicle need
not be immediately stopped.";
CM_ SG_ 2566741246 RedStopLampStatus "This lamp is uesed to relay trouble code information that is of a severe enought condition that it warrants stopping the vehicle.";
CM_ SG_ 2566741246 ProtectLampStatus "This lamp is used to relay trouble code informatio that is reporting a problem with a vehicle system that is most
probably not electronic subsystem related.";
CM_ BO_ 2566741502 "DTCs - A, Previously Active";
CM_ SG_ 2566741502 FlashRedStopLamp "This parameter provides the capability to flash the RSL (SPN 3039).";
CM_ SG_ 2566741502 FlashProtectLamp "This parameter provides the capability to flash the engine protect lamp (SPN 3041).";
CM_ SG_ 2566741502 FlashMalfuncIndicatorLamp "This parameter provides the capability to flash the MIL (SPN 3038).";
CM_ SG_ 2566741502 FlashAmberWarningLamp "This parameter provides the capability to flash the AWL (SPN 3040). ";
CM_ SG_ 2566741502 MalfunctionIndicatorLampStatus "A lamp used to relay only emissions-related trouble code information.";
CM_ SG_ 2566741502 AmberWarningLampStatus "This lamp is used to relay trouble code information that is reporting a problem with the vehicle system but the vehicle need
not be immediately stopped.";
CM_ SG_ 2566741502 RedStopLampStatus "This lamp is uesed to relay trouble code information that is of a severe enought condition that it warrants stopping the vehicle.";
CM_ SG_ 2566741502 ProtectLampStatus "This lamp is used to relay trouble code informatio that is reporting a problem with a vehicle system that is most
probably not electronic subsystem related.";
CM_ BO_ 2566741758 "DTCs - A, Confirmed and Active";
CM_ SG_ 2566741758 FlashRedStopLamp "This parameter provides the capability to flash the RSL (SPN 3039).";
CM_ SG_ 2566741758 FlashProtectLamp "This parameter provides the capability to flash the engine protect lamp (SPN 3041).";
CM_ SG_ 2566741758 FlashMalfuncIndicatorLamp "This parameter provides the capability to flash the MIL (SPN 3038).";
CM_ SG_ 2566741758 FlashAmberWarningLamp "This parameter provides the capability to flash the AWL (SPN 3040). ";
CM_ SG_ 2566741758 MalfunctionIndicatorLampStatus "A lamp used to relay only emissions-related trouble code information.";
CM_ SG_ 2566741758 AmberWarningLampStatus "This lamp is used to relay trouble code information that is reporting a problem with the vehicle system but the vehicle need
not be immediately stopped.";
CM_ SG_ 2566741758 RedStopLampStatus "This lamp is uesed to relay trouble code information that is of a severe enought condition that it warrants stopping the vehicle.";
CM_ SG_ 2566741758 ProtectLampStatus "This lamp is used to relay trouble code informatio that is reporting a problem with a vehicle system that is most
probably not electronic subsystem related.";
CM_ BO_ 2566742014 "DTCs - A, Pending";
CM_ SG_ 2566742014 FlashRedStopLamp "This parameter provides the capability to flash the RSL (SPN 3039).";
CM_ SG_ 2566742014 FlashProtectLamp "This parameter provides the capability to flash the engine protect lamp (SPN 3041).";
CM_ SG_ 2566742014 FlashMalfuncIndicatorLamp "This parameter provides the capability to flash the MIL (SPN 3038).";
CM_ SG_ 2566742014 FlashAmberWarningLamp "This parameter provides the capability to flash the AWL (SPN 3040). ";
CM_ SG_ 2566742014 MalfunctionIndicatorLampStatus "A lamp used to relay only emissions-related trouble code information.";
CM_ SG_ 2566742014 AmberWarningLampStatus "This lamp is used to relay trouble code information that is reporting a problem with the vehicle system but the vehicle need
not be immediately stopped.";
CM_ SG_ 2566742014 RedStopLampStatus "This lamp is uesed to relay trouble code information that is of a severe enought condition that it warrants stopping the vehicle.";
CM_ SG_ 2566742014 ProtectLampStatus "This lamp is used to relay trouble code informatio that is reporting a problem with a vehicle system that is most
probably not electronic subsystem related.";
CM_ BO_ 2560622334 "Immediate Fault Status";
CM_ SG_ 2560622334 FlashRedStopLamp "This parameter provides the capability to flash the RSL (SPN 3039).";
CM_ SG_ 2560622334 FlashProtectLamp "This parameter provides the capability to flash the engine protect lamp (SPN 3041).";
CM_ SG_ 2560622334 FlashMalfuncIndicatorLamp "This parameter provides the capability to flash the MIL (SPN 3038).";
CM_ SG_ 2560622334 FlashAmberWarningLamp "This parameter provides the capability to flash the AWL (SPN 3040). ";
CM_ SG_ 2560622334 MalfunctionIndicatorLampStatus "A lamp used to relay only emissions-related trouble code information.";
CM_ SG_ 2560622334 AmberWarningLampStatus "This lamp is used to relay trouble code information that is reporting a problem with the vehicle system but the vehicle need
not be immediately stopped.";
CM_ SG_ 2560622334 RedStopLampStatus "This lamp is uesed to relay trouble code information that is of a severe enought condition that it warrants stopping the vehicle.";
CM_ SG_ 2560622334 ProtectLampStatus "This lamp is used to relay trouble code informatio that is reporting a problem with a vehicle system that is most
probably not electronic subsystem related.";
CM_ BO_ 2560556798 "DTC Counts";
CM_ SG_ 2560556798 PermanentDTCs "Identifies the current number of permanent DTCs";
CM_ SG_ 2560556798 PreviouslyMILOnDTCs "Identifies the current number of previously MIL-On DTCs";
CM_ SG_ 2560556798 MILOnDTCs "Identifies the current number of MIL-On DTCs";
CM_ SG_ 2560556798 AllPendingDTCs "Identifies the current total number of pending DTCs, including emission related";
CM_ SG_ 2560556798 PendingDTCs "Identifies the current number of emission related pending DTCs";
CM_ BO_ 2566750462 "Emission-Related Permanent Diagnostic Trouble Codes";
CM_ SG_ 2566750462 FlashRedStopLamp "This parameter provides the capability to flash the RSL (SPN 3039).";
CM_ SG_ 2566750462 FlashProtectLamp "This parameter provides the capability to flash the engine protect lamp (SPN 3041).";
CM_ SG_ 2566750462 FlashMalfuncIndicatorLamp "This parameter provides the capability to flash the MIL (SPN 3038).";
CM_ SG_ 2566750462 FlashAmberWarningLamp "This parameter provides the capability to flash the AWL (SPN 3040). ";
CM_ SG_ 2566750462 MalfunctionIndicatorLampStatus "A lamp used to relay only emissions-related trouble code information.";
CM_ SG_ 2566750462 AmberWarningLampStatus "This lamp is used to relay trouble code information that is reporting a problem with the vehicle system but the vehicle need
not be immediately stopped.";
CM_ SG_ 2566750462 RedStopLampStatus "This lamp is uesed to relay trouble code information that is of a severe enought condition that it warrants stopping the vehicle.";
CM_ SG_ 2566750462 ProtectLampStatus "This lamp is used to relay trouble code informatio that is reporting a problem with a vehicle system that is most
probably not electronic subsystem related.";
CM_ BO_ 2566750974 "All Pending DTCs";
CM_ SG_ 2566750974 FlashRedStopLamp "This parameter provides the capability to flash the RSL (SPN 3039).";
CM_ SG_ 2566750974 FlashProtectLamp "This parameter provides the capability to flash the engine protect lamp (SPN 3041).";
CM_ SG_ 2566750974 FlashMalfuncIndicatorLamp "This parameter provides the capability to flash the MIL (SPN 3038).";
CM_ SG_ 2566750974 FlashAmberWarningLamp "This parameter provides the capability to flash the AWL (SPN 3040). ";
CM_ SG_ 2566750974 MalfunctionIndicatorLampStatus "A lamp used to relay only emissions-related trouble code information.";
CM_ SG_ 2566750974 AmberWarningLampStatus "This lamp is used to relay trouble code information that is reporting a problem with the vehicle system but the vehicle need
not be immediately stopped.";
CM_ SG_ 2566750974 RedStopLampStatus "This lamp is uesed to relay trouble code information that is of a severe enought condition that it warrants stopping the vehicle.";
CM_ SG_ 2566750974 ProtectLampStatus "This lamp is used to relay trouble code informatio that is reporting a problem with a vehicle system that is most
probably not electronic subsystem related.";
CM_ BO_ 2560818942 "Regulated Exhaust Emission Level Exceedance. This message provides the DTCs and associated timers";
CM_ SG_ 2560818942 DTCTimeUntilDerate "This timer provides the number of hours the malfunction has until the OBD required derate will occur";
CM_ SG_ 2560818942 DTCTotalPreviouslyActiveTime "This timer provides the number of hours the NOx malfunction has been confirmed and previously active";
CM_ SG_ 2560818942 DTCTotalActiveTime "This timer provides the total number of hours the DTC has been confirmed and active";
CM_ SG_ 2560818942 DM32_01FMI "The FMI defines the type of failure detected in the subsystem identified by an SPN.";
CM_ SG_ 2560818942 DM32_01SPN_High "SPN #1 (Conversion Version 4)";
CM_ SG_ 2560818942 DM32_01SPN "SPN #1 (Conversion Version 4)";
BA_DEF_ SG_  "SigType" ENUM  "Default","Range","RangeSigned","ASCII","Discrete","Control","ReferencePGN","DTC","StringDelimiter","StringLength","StringLengthControl";
BA_DEF_ SG_  "GenSigStartValue" INT 0 10000;
BA_DEF_ SG_  "GenSigSendType" ENUM  "Cyclic","OnWrite","reserved","OnChange","reserved","reserved","reserved","NoSigSendType";
BA_DEF_ SG_  "GenSigILSupport" ENUM  "Yes","No";
BA_DEF_ SG_  "GenSigEVName" STRING ;
BA_DEF_ SG_  "SPN" INT 0 524287;
BA_DEF_ BO_  "GenMsgILSupport" ENUM  "Yes","No";
BA_DEF_ BO_  "GenMsgRequestable" INT 0 1;
BA_DEF_ BO_  "GenMsgSendType" ENUM  "cyclic","reserved","cyclicIfActive","reserved","reserved","reserved","reserved","reserved","noMsgSendType";
BA_DEF_ BO_  "VFrameFormat" ENUM  "StandardCAN","ExtendedCAN","reserved","J1939PG";
BA_DEF_ SG_  "SystemSignalLongSymbol" STRING ;
BA_DEF_DEF_  "SigType" "Default";
BA_DEF_DEF_  "GenSigStartValue" 0;
BA_DEF_DEF_  "GenSigSendType" "NoSigSendType";
BA_DEF_DEF_  "GenSigILSupport" "Yes";
BA_DEF_DEF_  "GenSigEVName" "Env@Nodename_@Signame";
BA_DEF_DEF_  "SPN" 0;
BA_DEF_DEF_  "GenMsgILSupport" "Yes";
BA_DEF_DEF_  "GenMsgRequestable" 1;
BA_DEF_DEF_  "GenMsgSendType" "noMsgSendType";
BA_DEF_DEF_  "VFrameFormat" "J1939PG";
BA_DEF_DEF_  "SystemSignalLongSymbol" "";
BA_ "SPN" SG_ 2566739710 FlashRedStopLamp 3039;
BA_ "SigType" SG_ 2566739710 FlashRedStopLamp 4;
BA_ "SPN" SG_ 2566739710 FlashProtectLamp 3041;
BA_ "SigType" SG_ 2566739710 FlashProtectLamp 4;
BA_ "SPN" SG_ 2566739710 FlashMalfuncIndicatorLamp 3038;
BA_ "SigType" SG_ 2566739710 FlashMalfuncIndicatorLamp 4;
BA_ "SPN" SG_ 2566739710 FlashAmberWarningLamp 3040;
BA_ "SigType" SG_ 2566739710 FlashAmberWarningLamp 4;
BA_ "SPN" SG_ 2566739710 MalfunctionIndicatorLampStatus 1213;
BA_ "SigType" SG_ 2566739710 MalfunctionIndicatorLampStatus 4;
BA_ "SPN" SG_ 2566739710 AmberWarningLampStatus 624;
BA_ "SigType" SG_ 2566739710 AmberWarningLampStatus 4;
BA_ "SPN" SG_ 2566739710 RedStopLampStatus 623;
BA_ "SigType" SG_ 2566739710 RedStopLampStatus 4;
BA_ "SPN" SG_ 2566739710 ProtectLampStatus 987;
BA_ "SigType" SG_ 2566739710 ProtectLampStatus 4;
BA_ "SPN" SG_ 2566739966 FlashRedStopLamp 3039;
BA_ "SigType" SG_ 2566739966 FlashRedStopLamp 4;
BA_ "SPN" SG_ 2566739966 FlashProtectLamp 3041;
BA_ "SigType" SG_ 2566739966 FlashProtectLamp 4;
BA_ "SPN" SG_ 2566739966 FlashMalfuncIndicatorLamp 3038;
BA_ "SigType" SG_ 2566739966 FlashMalfuncIndicatorLamp 4;
BA_ "SPN" SG_ 2566739966 FlashAmberWarningLamp 3040;
BA_ "SigType" SG_ 2566739966 FlashAmberWarningLamp 4;
BA_ "SPN" SG_ 2566739966 MalfunctionIndicatorLampStatus 1213;
BA_ "SigType" SG_ 2566739966 MalfunctionIndicatorLampStatus 4;
BA_ "SPN" SG_ 2566739966 AmberWarningLampStatus 624;
BA_ "SigType" SG_ 2566739966 AmberWarningLampStatus 4;
BA_ "SPN" SG_ 2566739966 RedStopLampStatus 623;
BA_ "SigType" SG_ 2566739966 RedStopLampStatus 4;
BA_ "SPN" SG_ 2566739966 ProtectLampStatus 987;
BA_ "SigType" SG_ 2566739966 ProtectLampStatus 4;
BA_ "SPN" SG_ 2566740222 FlashRedStopLamp 3039;
BA_ "SigType" SG_ 2566740222 FlashRedStopLamp 4;
BA_ "SPN" SG_ 2566740222 FlashProtectLamp 3041;
BA_ "SigType" SG_ 2566740222 FlashProtectLamp 4;
BA_ "SPN" SG_ 2566740222 FlashMalfuncIndicatorLamp 3038;
BA_ "SigType" SG_ 2566740222 FlashMalfuncIndicatorLamp 4;
BA_ "SPN" SG_ 2566740222 FlashAmberWarningLamp 3040;
BA_ "SigType" SG_ 2566740222 FlashAmberWarningLamp 4;
BA_ "SPN" SG_ 2566740222 MalfunctionIndicatorLampStatus 1213;
BA_ "SigType" SG_ 2566740222 MalfunctionIndicatorLampStatus 4;
BA_ "SPN" SG_ 2566740222 AmberWarningLampStatus 624;
BA_ "SigType" SG_ 2566740222 AmberWarningLampStatus 4;
BA_ "SPN" SG_ 2566740222 RedStopLampStatus 623;
BA_ "SigType" SG_ 2566740222 RedStopLampStatus 4;
BA_ "SPN" SG_ 2566740222 ProtectLampStatus 987;
BA_ "SigType" SG_ 2566740222 ProtectLampStatus 4;
BA_ "SPN" SG_ 2566740478 FlashRedStopLamp 3039;
BA_ "SigType" SG_ 2566740478 FlashRedStopLamp 4;
BA_ "SPN" SG_ 2566740478 FlashProtectLamp 3041;
BA_ "SigType" SG_ 2566740478 FlashProtectLamp 4;
BA_ "SPN" SG_ 2566740478 FlashMalfuncIndicatorLamp 3038;
BA_ "SigType" SG_ 2566740478 FlashMalfuncIndicatorLamp 4;
BA_ "SPN" SG_ 2566740478 FlashAmberWarningLamp 3040;
BA_ "SigType" SG_ 2566740478 FlashAmberWarningLamp 4;
BA_ "SPN" SG_ 2566740478 MalfunctionIndicatorLampStatus 1213;
BA_ "SigType" SG_ 2566740478 MalfunctionIndicatorLampStatus 4;
BA_ "SPN" SG_ 2566740478 AmberWarningLampStatus 624;
BA_ "SigType" SG_ 2566740478 AmberWarningLampStatus 4;
BA_ "SPN" SG_ 2566740478 RedStopLampStatus 623;
BA_ "SigType" SG_ 2566740478 RedStopLampStatus 4;
BA_ "SPN" SG_ 2566740478 ProtectLampStatus 987;
BA_ "SigType" SG_ 2566740478 ProtectLampStatus 4;
BA_ "SPN" SG_ 2566740734 FlashRedStopLamp 3039;
BA_ "SigType" SG_ 2566740734 FlashRedStopLamp 4;
BA_ "SPN" SG_ 2566740734 FlashProtectLamp 3041;
BA_ "SigType" SG_ 2566740734 FlashProtectLamp 4;
BA_ "SPN" SG_ 2566740734 FlashMalfuncIndicatorLamp 3038;
BA_ "SigType" SG_ 2566740734 FlashMalfuncIndicatorLamp 4;
BA_ "SPN" SG_ 2566740734 FlashAmberWarningLamp 3040;
BA_ "SigType" SG_ 2566740734 FlashAmberWarningLamp 4;
BA_ "SPN" SG_ 2566740734 MalfunctionIndicatorLampStatus 1213;
BA_ "SigType" SG_ 2566740734 MalfunctionIndicatorLampStatus 4;
BA_ "SPN" SG_ 2566740734 AmberWarningLampStatus 624;
BA_ "SigType" SG_ 2566740734 AmberWarningLampStatus 4;
BA_ "SPN" SG_ 2566740734 RedStopLampStatus 623;
BA_ "SigType" SG_ 2566740734 RedStopLampStatus 4;
BA_ "SPN" SG_ 2566740734 ProtectLampStatus 987;
BA_ "SigType" SG_ 2566740734 ProtectLampStatus 4;
BA_ "SPN" SG_ 2566740990 FlashRedStopLamp 3039;
BA_ "SigType" SG_ 2566740990 FlashRedStopLamp 4;
BA_ "SPN" SG_ 2566740990 FlashProtectLamp 3041;
BA_ "SigType" SG_ 2566740990 FlashProtectLamp 4;
BA_ "SPN" SG_ 2566740990 FlashMalfuncIndicatorLamp 3038;
BA_ "SigType" SG_ 2566740990 FlashMalfuncIndicatorLamp 4;
BA_ "SPN" SG_ 2566740990 FlashAmberWarningLamp 3040;
BA_ "SigType" SG_ 2566740990 FlashAmberWarningLamp 4;
BA_ "SPN" SG_ 2566740990 MalfunctionIndicatorLampStatus 1213;
BA_ "SigType" SG_ 2566740990 MalfunctionIndicatorLampStatus 4;
BA_ "SPN" SG_ 2566740990 AmberWarningLampStatus 624;
BA_ "SigType" SG_ 2566740990 AmberWarningLampStatus 4;
BA_ "SPN" SG_ 2566740990 RedStopLampStatus 623;
BA_ "SigType" SG_ 2566740990 RedStopLampStatus 4;
BA_ "SPN" SG_ 2566740990 ProtectLampStatus 987;
BA_ "SigType" SG_ 2566740990 ProtectLampStatus 4;
BA_ "SPN" SG_ 2566741246 FlashRedStopLamp 3039;
BA_ "SigType" SG_ 2566741246 FlashRedStopLamp 4;
BA_ "SPN" SG_ 2566741246 FlashProtectLamp 3041;
BA_ "SigType" SG_ 2566741246 FlashProtectLamp 4;
BA_ "SPN" SG_ 2566741246 FlashMalfuncIndicatorLamp 3038;
BA_ "SigType" SG_ 2566741246 FlashMalfuncIndicatorLamp 4;
BA_ "SPN" SG_ 2566741246 FlashAmberWarningLamp 3040;
BA_ "SigType" SG_ 2566741246 FlashAmberWarningLamp 4;
BA_ "SPN" SG_ 2566741246 MalfunctionIndicatorLampStatus 1213;
BA_ "SigType" SG_ 2566741246 MalfunctionIndicatorLampStatus 4;
BA_ "SPN" SG_ 2566741246 AmberWarningLampStatus 624;
BA_ "SigType" SG_ 2566741246 AmberWarningLampStatus 4;
BA_ "SPN" SG_ 2566741246 RedStopLampStatus 623;
BA_ "SigType" SG_ 2566741246 RedStopLampStatus 4;
BA_ "SPN" SG_ 2566741246 ProtectLampStatus 987;
BA_ "SigType" SG_ 2566741246 ProtectLampStatus 4;
BA_ "SPN" SG_ 2566741502 FlashRedStopLamp 3039;
BA_ "SigType" SG_ 2566741502 FlashRedStopLamp 4;
BA_ "SPN" SG_ 2566741502 FlashProtectLamp 3041;
BA_ "SigType" SG_ 2566741502 FlashProtectLamp 4;
BA_ "SPN" SG_ 2566741502 FlashMalfuncIndicatorLamp 3038;
BA_ "SigType" SG_ 2566741502 FlashMalfuncIndicatorLamp 4;
BA_ "SPN" SG_ 2566741502 FlashAmberWarningLamp 3040;
BA_ "SigType" SG_ 2566741502 FlashAmberWarningLamp 4;
BA_ "SPN" SG_ 2566741502 MalfunctionIndicatorLampStatus 1213;
BA_ "SigType" SG_ 2566741502 MalfunctionIndicatorLampStatus 4;
BA_ "SPN" SG_ 2566741502 AmberWarningLampStatus 624;
BA_ "SigType" SG_ 2566741502 AmberWarningLampStatus 4;
BA_ "SPN" SG_ 2566741502 RedStopLampStatus 623;
BA_ "SigType" SG_ 2566741502 RedStopLampStatus 4;
BA_ "SPN" SG_ 2566741502 ProtectLampStatus 987;
BA_ "SigType" SG_ 2566741502 ProtectLampStatus 4;
BA_ "SPN" SG_ 2566741758 FlashRedStopLamp 3039;
BA_ "SigType" SG_ 2566741758 FlashRedStopLamp 4;
BA_ "SPN" SG_ 2566741758 FlashProtectLamp 3041;
BA_ "SigType" SG_ 2566741758 FlashProtectLamp 4;
BA_ "SPN" SG_ 2566741758 FlashMalfuncIndicatorLamp 3038;
BA_ "SigType" SG_ 2566741758 FlashMalfuncIndicatorLamp 4;
BA_ "SPN" SG_ 2566741758 FlashAmberWarningLamp 3040;
BA_ "SigType" SG_ 2566741758 FlashAmberWarningLamp 4;
BA_ "SPN" SG_ 2566741758 MalfunctionIndicatorLampStatus 1213;
BA_ "SigType" SG_ 2566741758 MalfunctionIndicatorLampStatus 4;
BA_ "SPN" SG_ 2566741758 AmberWarningLampStatus 624;
BA_ "SigType" SG_ 2566741758 AmberWarningLampStatus 4;
BA_ "SPN" SG_ 2566741758 RedStopLampStatus 623;
BA_ "SigType" SG_ 2566741758 RedStopLampStatus 4;
BA_ "SPN" SG_ 2566741758 ProtectLampStatus 987;
BA_ "SigType" SG_ 2566741758 ProtectLampStatus 4;
BA_ "SPN" SG_ 2566742014 FlashRedStopLamp 3039;
BA_ "SigType" SG_ 2566742014 FlashRedStopLamp 4;
BA_ "SPN" SG_ 2566742014 FlashProtectLamp 3041;
BA_ "SigType" SG_ 2566742014 FlashProtectLamp 4;
BA_ "SPN" SG_ 2566742014 FlashMalfuncIndicatorLamp 3038;
BA_ "SigType" SG_ 2566742014 FlashMalfuncIndicatorLamp 4;
BA_ "SPN" SG_ 2566742014 FlashAmberWarningLamp 3040;
BA_ "SigType" SG_ 2566742014 FlashAmberWarningLamp 4;
BA_ "SPN" SG_ 2566742014 MalfunctionIndicatorLampStatus 1213;
BA_ "SigType" SG_ 2566742014 MalfunctionIndicatorLampStatus 4;
BA_ "SPN" SG_ 2566742014 AmberWarningLampStatus 624;
BA_ "SigType" SG_ 2566742014 AmberWarningLampStatus 4;
BA_ "SPN" SG_ 2566742014 RedStopLampStatus 623;
BA_ "SigType" SG_ 2566742014 RedStopLampStatus 4;
BA_ "SPN" SG_ 2566742014 ProtectLampStatus 987;
BA_ "SigType" SG_ 2566742014 ProtectLampStatus 4;
BA_ "SPN" SG_ 2560622334 FlashRedStopLamp 3039;
BA_ "SigType" SG_ 2560622334 FlashRedStopLamp 4;
BA_ "SPN" SG_ 2560622334 FlashProtectLamp 3041;
BA_ "SigType" SG_ 2560622334 FlashProtectLamp 4;
BA_ "SPN" SG_ 2560622334 FlashMalfuncIndicatorLamp 3038;
BA_ "SigType" SG_ 2560622334 FlashMalfuncIndicatorLamp 4;
BA_ "SPN" SG_ 2560622334 FlashAmberWarningLamp 3040;
BA_ "SigType" SG_ 2560622334 FlashAmberWarningLamp 4;
BA_ "SPN" SG_ 2560622334 MalfunctionIndicatorLampStatus 1213;
BA_ "SigType" SG_ 2560622334 MalfunctionIndicatorLampStatus 4;
BA_ "SPN" SG_ 2560622334 AmberWarningLampStatus 624;
BA_ "SigType" SG_ 2560622334 AmberWarningLampStatus 4;
BA_ "SPN" SG_ 2560622334 RedStopLampStatus 623;
BA_ "SigType" SG_ 2560622334 RedStopLampStatus 4;
BA_ "SPN" SG_ 2560622334 ProtectLampStatus 987;
BA_ "SigType" SG_ 2560622334 ProtectLampStatus 4;
BA_ "SPN" SG_ 2560556798 PermanentDTCs 4108;
BA_ "SigType" SG_ 2560556798 PermanentDTCs 1;
BA_ "SPN" SG_ 2560556798 PreviouslyMILOnDTCs 4107;
BA_ "SigType" SG_ 2560556798 PreviouslyMILOnDTCs 1;
BA_ "SPN" SG_ 2560556798 MILOnDTCs 4106;
BA_ "SigType" SG_ 2560556798 MILOnDTCs 1;
BA_ "SPN" SG_ 2560556798 AllPendingDTCs 4105;
BA_ "SigType" SG_ 2560556798 AllPendingDTCs 1;
BA_ "SPN" SG_ 2560556798 PendingDTCs 4104;
BA_ "SigType" SG_ 2560556798 PendingDTCs 1;
BA_ "SPN" SG_ 2566750462 FlashRedStopLamp 3039;
BA_ "SigType" SG_ 2566750462 FlashRedStopLamp 4;
BA_ "SPN" SG_ 2566750462 FlashProtectLamp 3041;
BA_ "SigType" SG_ 2566750462 FlashProtectLamp 4;
BA_ "SPN" SG_ 2566750462 FlashMalfuncIndicatorLamp 3038;
BA_ "SigType" SG_ 2566750462 FlashMalfuncIndicatorLamp 4;
BA_ "SPN" SG_ 2566750462 FlashAmberWarningLamp 3040;
BA_ "SigType" SG_ 2566750462 FlashAmberWarningLamp 4;
BA_ "SPN" SG_ 2566750462 MalfunctionIndicatorLampStatus 1213;
BA_ "SigType" SG_ 2566750462 MalfunctionIndicatorLampStatus 4;
BA_ "SPN" SG_ 2566750462 AmberWarningLampStatus 624;
BA_ "SigType" SG_ 2566750462 AmberWarningLampStatus 4;
BA_ "SPN" SG_ 2566750462 RedStopLampStatus 623;
BA_ "SigType" SG_ 2566750462 RedStopLampStatus 4;
BA_ "SPN" SG_ 2566750462 ProtectLampStatus 987;
BA_ "SigType" SG_ 2566750462 ProtectLampStatus 4;
BA_ "SPN" SG_ 2566750974 FlashRedStopLamp 3039;
BA_ "SigType" SG_ 2566750974 FlashRedStopLamp 4;
BA_ "SPN" SG_ 2566750974 FlashProtectLamp 3041;
BA_ "SigType" SG_ 2566750974 FlashProtectLamp 4;
BA_ "SPN" SG_ 2566750974 FlashMalfuncIndicatorLamp 3038;
BA_ "SigType" SG_ 2566750974 FlashMalfuncIndicatorLamp 4;
BA_ "SPN" SG_ 2566750974 FlashAmberWarningLamp 3040;
BA_ "SigType" SG_ 2566750974 FlashAmberWarningLamp 4;
BA_ "SPN" SG_ 2566750974 MalfunctionIndicatorLampStatus 1213;
BA_ "SigType" SG_ 2566750974 MalfunctionIndicatorLampStatus 4;
BA_ "SPN" SG_ 2566750974 AmberWarningLampStatus 624;
BA_ "SigType" SG_ 2566750974 AmberWarningLampStatus 4;
BA_ "SPN" SG_ 2566750974 RedStopLampStatus 623;
BA_ "SigType" SG_ 2566750974 RedStopLampStatus 4;
BA_ "SPN" SG_ 2566750974 ProtectLampStatus 987;
BA_ "SigType" SG_ 2566750974 ProtectLampStatus 4;
BA_ "SPN" SG_ 2560818942 DTCTimeUntilDerate 4123;
BA_ "SigType" SG_ 2560818942 DTCTimeUntilDerate 1;
BA_ "SPN" SG_ 2560818942 DTCTotalPreviouslyActiveTime 4122;
BA_ "SigType" SG_ 2560818942 DTCTotalPreviouslyActiveTime 1;
BA_ "SPN" SG_ 2560818942 DTCTotalActiveTime 4121;
BA_ "SigType" SG_ 2560818942 DTCTotalActiveTime 1;
BA_ "SPN" SG_ 2560818942 DM32_01FMI 1215;
BA_ "SPN" SG_ 2560818942 DM32_01SPN_High 1214;
BA_ "SPN" SG_ 2560818942 DM32_01SPN 1214;
VAL_ 2566739710 FlashRedStopLamp 3 "Unavailable / Do Not Flash" 2 "Reserved" 1 "Fast Flash" 0 "Slow Flash" ;
VAL_ 2566739710 FlashProtectLamp 3 "Unavailable / Do Not Flash" 2 "Reserved" 1 "Fast Flash" 0 "Slow Flash" ;
VAL_ 2566739710 FlashMalfuncIndicatorLamp 3 "Unavailable / Do Not Flash" 2 "Reserved" 1 "Fast Flash" 0 "Slow Flash" ;
VAL_ 2566739710 FlashAmberWarningLamp 3 "Unavailable / Do Not Flash" 2 "Reserved" 1 "Fast Flash" 0 "Slow Flash" ;
VAL_ 2566739710 MalfunctionIndicatorLampStatus 3 "Not available" 2 "Reserved" 1 "Lamp on" 0 "Lamp off" ;
VAL_ 2566739710 AmberWarningLampStatus 3 "Not available" 2 "Reserved" 1 "Lamp on" 0 "Lamp off" ;
VAL_ 2566739710 RedStopLampStatus 3 "Not available" 2 "Reserved" 1 "Lamp on" 0 "Lamp off" ;
VAL_ 2566739710 ProtectLampStatus 3 "Not available" 2 "Reserved" 1 "Lamp on" 0 "Lamp off" ;
VAL_ 2566739966 FlashRedStopLamp 3 "Unavailable / Do Not Flash" 2 "Reserved" 1 "Fast Flash" 0 "Slow Flash" ;
VAL_ 2566739966 FlashProtectLamp 3 "Unavailable / Do Not Flash" 2 "Reserved" 1 "Fast Flash" 0 "Slow Flash" ;
VAL_ 2566739966 FlashMalfuncIndicatorLamp 3 "Unavailable / Do Not Flash" 2 "Reserved" 1 "Fast Flash" 0 "Slow Flash" ;
VAL_ 2566739966 FlashAmberWarningLamp 3 "Unavailable / Do Not Flash" 2 "Reserved" 1 "Fast Flash" 0 "Slow Flash" ;
VAL_ 2566739966 MalfunctionIndicatorLampStatus 3 "Not available" 2 "Reserved" 1 "Lamp on" 0 "Lamp off" ;
VAL_ 2566739966 AmberWarningLampStatus 3 "Not available" 2 "Reserved" 1 "Lamp on" 0 "Lamp off" ;
VAL_ 2566739966 RedStopLampStatus 3 "Not available" 2 "Reserved" 1 "Lamp on" 0 "Lamp off" ;
VAL_ 2566739966 ProtectLampStatus 3 "Not available" 2 "Reserved" 1 "Lamp on" 0 "Lamp off" ;
VAL_ 2566740222 FlashRedStopLamp 3 "Unavailable / Do Not Flash" 2 "Reserved" 1 "Fast Flash" 0 "Slow Flash" ;
VAL_ 2566740222 FlashProtectLamp 3 "Unavailable / Do Not Flash" 2 "Reserved" 1 "Fast Flash" 0 "Slow Flash" ;
VAL_ 2566740222 FlashMalfuncIndicatorLamp 3 "Unavailable / Do Not Flash" 2 "Reserved" 1 "Fast Flash" 0 "Slow Flash" ;
VAL_ 2566740222 FlashAmberWarningLamp 3 "Unavailable / Do Not Flash" 2 "Reserved" 1 "Fast Flash" 0 "Slow Flash" ;
VAL_ 2566740222 MalfunctionIndicatorLampStatus 3 "Not available" 2 "Reserved" 1 "Lamp on" 0 "Lamp off" ;
VAL_ 2566740222 AmberWarningLampStatus 3 "Not available" 2 "Reserved" 1 "Lamp on" 0 "Lamp off" ;
VAL_ 2566740222 RedStopLampStatus 3 "Not available" 2 "Reserved" 1 "Lamp on" 0 "Lamp off" ;
VAL_ 2566740222 ProtectLampStatus 3 "Not available" 2 "Reserved" 1 "Lamp on" 0 "Lamp off" ;
VAL_ 2566740478 FlashRedStopLamp 3 "Unavailable / Do Not Flash" 2 "Reserved" 1 "Fast Flash" 0 "Slow Flash" ;
VAL_ 2566740478 FlashProtectLamp 3 "Unavailable / Do Not Flash" 2 "Reserved" 1 "Fast Flash" 0 "Slow Flash" ;
VAL_ 2566740478 FlashMalfuncIndicatorLamp 3 "Unavailable / Do Not Flash" 2 "Reserved" 1 "Fast Flash" 0 "Slow Flash" ;
VAL_ 2566740478 FlashAmberWarningLamp 3 "Unavailable / Do Not Flash" 2 "Reserved" 1 "Fast Flash" 0 "Slow Flash" ;
VAL_ 2566740478 MalfunctionIndicatorLampStatus 3 "Not available" 2 "Reserved" 1 "Lamp on" 0 "Lamp off" ;
VAL_ 2566740478 AmberWarningLampStatus 3 "Not available" 2 "Reserved" 1 "Lamp on" 0 "Lamp off" ;
VAL_ 2566740478 RedStopLampStatus 3 "Not available" 2 "Reserved" 1 "Lamp on" 0 "Lamp off" ;
VAL_ 2566740478 ProtectLampStatus 3 "Not available" 2 "Reserved" 1 "Lamp on" 0 "Lamp off" ;
VAL_ 2566740734 FlashRedStopLamp 3 "Unavailable / Do Not Flash" 2 "Reserved" 1 "Fast Flash" 0 "Slow Flash" ;
VAL_ 2566740734 FlashProtectLamp 3 "Unavailable / Do Not Flash" 2 "Reserved" 1 "Fast Flash" 0 "Slow Flash" ;
VAL_ 2566740734 FlashMalfuncIndicatorLamp 3 "Unavailable / Do Not Flash" 2 "Reserved" 1 "Fast Flash" 0 "Slow Flash" ;
VAL_ 2566740734 FlashAmberWarningLamp 3 "Unavailable / Do Not Flash" 2 "Reserved" 1 "Fast Flash" 0 "Slow Flash" ;
VAL_ 2566740734 MalfunctionIndicatorLampStatus 3 "Not available" 2 "Reserved" 1 "Lamp on" 0 "Lamp off" ;
VAL_ 2566740734 AmberWarningLampStatus 3 "Not available" 2 "Reserved" 1 "Lamp on" 0 "Lamp off" ;
VAL_ 2566740734 RedStopLampStatus 3 "Not available" 2 "Reserved" 1 "Lamp on" 0 "Lamp off" ;
VAL_ 2566740734 ProtectLampStatus 3 "Not available" 2 "Reserved" 1 "Lamp on" 0 "Lamp off" ;
VAL_ 2566740990 FlashRedStopLamp 3 "Unavailable / Do Not Flash" 2 "Reserved" 1 "Fast Flash" 0 "Slow Flash" ;
VAL_ 2566740990 FlashProtectLamp 3 "Unavailable / Do Not Flash" 2 "Reserved" 1 "Fast Flash" 0 "Slow Flash" ;
VAL_ 2566740990 FlashMalfuncIndicatorLamp 3 "Unavailable / Do Not Flash" 2 "Reserved" 1 "Fast Flash" 0 "Slow Flash" ;
VAL_ 2566740990 FlashAmberWarningLamp 3 "Unavailable / Do Not Flash" 2 "Reserved" 1 "Fast Flash" 0 "Slow Flash" ;
VAL_ 2566740990 MalfunctionIndicatorLampStatus 3 "Not available" 2 "Reserved" 1 "Lamp on" 0 "Lamp off" ;
VAL_ 2566740990 AmberWarningLampStatus 3 "Not available" 2 "Reserved" 1 "Lamp on" 0 "Lamp off" ;
VAL_ 2566740990 RedStopLampStatus 3 "Not available" 2 "Reserved" 1 "Lamp on" 0 "Lamp off" ;
VAL_ 2566740990 ProtectLampStatus 3 "Not available" 2 "Reserved" 1 "Lamp on" 0 "Lamp off" ;
VAL_ 2566741246 FlashRedStopLamp 3 "Unavailable / Do Not Flash" 2 "Reserved" 1 "Fast Flash" 0 "Slow Flash" ;
VAL_ 2566741246 FlashProtectLamp 3 "Unavailable / Do Not Flash" 2 "Reserved" 1 "Fast Flash" 0 "Slow Flash" ;
VAL_ 2566741246 FlashMalfuncIndicatorLamp 3 "Unavailable / Do Not Flash" 2 "Reserved" 1 "Fast Flash" 0 "Slow Flash" ;
VAL_ 2566741246 FlashAmberWarningLamp 3 "Unavailable / Do Not Flash" 2 "Reserved" 1 "Fast Flash" 0 "Slow Flash" ;
VAL_ 2566741246 MalfunctionIndicatorLampStatus 3 "Not available" 2 "Reserved" 1 "Lamp on" 0 "Lamp off" ;
VAL_ 2566741246 AmberWarningLampStatus 3 "Not available" 2 "Reserved" 1 "Lamp on" 0 "Lamp off" ;
VAL_ 2566741246 RedStopLampStatus 3 "Not available" 2 "Reserved" 1 "Lamp on" 0 "Lamp off" ;
VAL_ 2566741246 ProtectLampStatus 3 "Not available" 2 "Reserved" 1 "Lamp on" 0 "Lamp off" ;
VAL_ 2566741502 FlashRedStopLamp 3 "Unavailable / Do Not Flash" 2 "Reserved" 1 "Fast Flash" 0 "Slow Flash" ;
VAL_ 2566741502 FlashProtectLamp 3 "Unavailable / Do Not Flash" 2 "Reserved" 1 "Fast Flash" 0 "Slow Flash" ;
VAL_ 2566741502 FlashMalfuncIndicatorLamp 3 "Unavailable / Do Not Flash" 2 "Reserved" 1 "Fast Flash" 0 "Slow Flash" ;
VAL_ 2566741502 FlashAmberWarningLamp 3 "Unavailable / Do Not Flash" 2 "Reserved" 1 "Fast Flash" 0 "Slow Flash" ;
VAL_ 2566741502 MalfunctionIndicatorLampStatus 3 "Not available" 2 "Reserved" 1 "Lamp on" 0 "Lamp off" ;
VAL_ 2566741502 AmberWarningLampStatus 3 "Not available" 2 "Reserved" 1 "Lamp on" 0 "Lamp off" ;
VAL_ 2566741502 RedStopLampStatus 3 "Not available" 2 "Reserved" 1 "Lamp on" 0 "Lamp off" ;
VAL_ 2566741502 ProtectLampStatus 3 "Not available" 2 "Reserved" 1 "Lamp on" 0 "Lamp off" ;
VAL_ 2566741758 FlashRedStopLamp 3 "Unavailable / Do Not Flash" 2 "Reserved" 1 "Fast Flash" 0 "Slow Flash" ;
VAL_ 2566741758 FlashProtectLamp 3 "Unavailable / Do Not Flash" 2 "Reserved" 1 "Fast Flash" 0 "Slow Flash" ;
VAL_ 2566741758 FlashMalfuncIndicatorLamp 3 "Unavailable / Do Not Flash" 2 "Reserved" 1 "Fast Flash" 0 "Slow Flash" ;
VAL_ 2566741758 FlashAmberWarningLamp 3 "Unavailable / Do Not Flash" 2 "Reserved" 1 "Fast Flash" 0 "Slow Flash" ;
VAL_ 2566741758 MalfunctionIndicatorLampStatus 3 "Not available" 2 "Reserved" 1 "Lamp on" 0 "Lamp off" ;
VAL_ 2566741758 AmberWarningLampStatus 3 "Not available" 2 "Reserved" 1 "Lamp on" 0 "Lamp off" ;
VAL_ 2566741758 RedStopLampStatus 3 "Not available" 2 "Reserved" 1 "Lamp on" 0 "Lamp off" ;
VAL_ 2566741758 ProtectLampStatus 3 "Not available" 2 "Reserved" 1 "Lamp on" 0 "Lamp off" ;
VAL_ 2566742014 FlashRedStopLamp 3 "Unavailable / Do Not Flash" 2 "Reserved" 1 "Fast Flash" 0 "Slow Flash" ;
VAL_ 2566742014 FlashProtectLamp 3 "Unavailable / Do Not Flash" 2 "Reserved" 1 "Fast Flash" 0 "Slow Flash" ;
VAL_ 2566742014 FlashMalfuncIndicatorLamp 3 "Unavailable / Do Not Flash" 2 "Reserved" 1 "Fast Flash" 0 "Slow Flash" ;
VAL_ 2566742014 FlashAmberWarningLamp 3 "Unavailable / Do Not Flash" 2 "Reserved" 1 "Fast Flash" 0 "Slow Flash" ;
VAL_ 2566742014 MalfunctionIndicatorLampStatus 3 "Not available" 2 "Reserved" 1 "Lamp on" 0 "Lamp off" ;
VAL_ 2566742014 AmberWarningLampStatus 3 "Not available" 2 "Reserved" 1 "Lamp on" 0 "Lamp off" ;
VAL_ 2566742014 RedStopLampStatus 3 "Not available" 2 "Reserved" 1 "Lamp on" 0 "Lamp off" ;
VAL_ 2566742014 ProtectLampStatus 3 "Not available" 2 "Reserved" 1 "Lamp on" 0 "Lamp off" ;
VAL_ 2560622334 FlashRedStopLamp 3 "Unavailable / Do Not Flash" 2 "Reserved" 1 "Fast Flash" 0 "Slow Flash" ;
VAL_ 2560622334 FlashProtectLamp 3 "Unavailable / Do Not Flash" 2 "Reserved" 1 "Fast Flash" 0 "Slow Flash" ;
VAL_ 2560622334 FlashMalfuncIndicatorLamp 3 "Unavailable / Do Not Flash" 2 "Reserved" 1 "Fast Flash" 0 "Slow Flash" ;
VAL_ 2560622334 FlashAmberWarningLamp 3 "Unavailable / Do Not Flash" 2 "Reserved" 1 "Fast Flash" 0 "Slow Flash" ;
VAL_ 2560622334 MalfunctionIndicatorLampStatus 3 "Not available" 2 "Reserved" 1 "Lamp on" 0 "Lamp off" ;
VAL_ 2560622334 AmberWarningLampStatus 3 "Not available" 2 "Reserved" 1 "Lamp on" 0 "Lamp off" ;
VAL_ 2560622334 RedStopLampStatus 3 "Not available" 2 "Reserved" 1 "Lamp on" 0 "Lamp off" ;
VAL_ 2560622334 ProtectLampStatus 3 "Not available" 2 "Reserved" 1 "Lamp on" 0 "Lamp off" ;
VAL_ 2566750462 FlashRedStopLamp 3 "Unavailable / Do Not Flash" 2 "Reserved" 1 "Fast Flash" 0 "Slow Flash" ;
VAL_ 2566750462 FlashProtectLamp 3 "Unavailable / Do Not Flash" 2 "Reserved" 1 "Fast Flash" 0 "Slow Flash" ;
VAL_ 2566750462 FlashMalfuncIndicatorLamp 3 "Unavailable / Do Not Flash" 2 "Reserved" 1 "Fast Flash" 0 "Slow Flash" ;
VAL_ 2566750462 FlashAmberWarningLamp 3 "Unavailable / Do Not Flash" 2 "Reserved" 1 "Fast Flash" 0 "Slow Flash" ;
VAL_ 2566750462 MalfunctionIndicatorLampStatus 3 "Not available" 2 "Reserved" 1 "Lamp on" 0 "Lamp off" ;
VAL_ 2566750462 AmberWarningLampStatus 3 "Not available" 2 "Reserved" 1 "Lamp on" 0 "Lamp off" ;
VAL_ 2566750462 RedStopLampStatus 3 "Not available" 2 "Reserved" 1 "Lamp on" 0 "Lamp off" ;
VAL_ 2566750462 ProtectLampStatus 3 "Not available" 2 "Reserved" 1 "Lamp on" 0 "Lamp off" ;
VAL_ 2566750974 FlashRedStopLamp 3 "Unavailable / Do Not Flash" 2 "Reserved" 1 "Fast Flash" 0 "Slow Flash" ;
VAL_ 2566750974 FlashProtectLamp 3 "Unavailable / Do Not Flash" 2 "Reserved" 1 "Fast Flash" 0 "Slow Flash" ;
VAL_ 2566750974 FlashMalfuncIndicatorLamp 3 "Unavailable / Do Not Flash" 2 "Reserved" 1 "Fast Flash" 0 "Slow Flash" ;
VAL_ 2566750974 FlashAmberWarningLamp 3 "Unavailable / Do Not Flash" 2 "Reserved" 1 "Fast Flash" 0 "Slow Flash" ;
VAL_ 2566750974 MalfunctionIndicatorLampStatus 3 "Not available" 2 "Reserved" 1 "Lamp on" 0 "Lamp off" ;
VAL_ 2566750974 AmberWarningLampStatus 3 "Not available" 2 "Reserved" 1 "Lamp on" 0 "Lamp off" ;
VAL_ 2566750974 RedStopLampStatus 3 "Not available" 2 "Reserved" 1 "Lamp on" 0 "Lamp off" ;
VAL_ 2566750974 ProtectLampStatus 3 "Not available" 2 "Reserved" 1 "Lamp on" 0 "Lamp off" ;
VAL_ 2560818942 DM32_01FMI 31 "Not available" 19 "Received network data in error" 18 "Below normal (moderately severe)" 17 "Below normal (least severe)" 16 "Above normal (moderately severe)" 15 "Above normal (least severe)" 14 "Special intstructions" 13 "Out of calibration" 12 "Bad intelligent device" 11 "Root cause not known" 10 "Abnormal rate of change" 9 "Abnormal update rate" 8 "Abnormal frequency" 7 "Mechanical system not responding" 6 "Current above normal" 5 "Current below normal" 4 "Voltage below normal" 3 "Voltage above normal" 2 "Data erratic" 1 "Below normal (most severe)" 0 "Above normal (most severe)" ;
